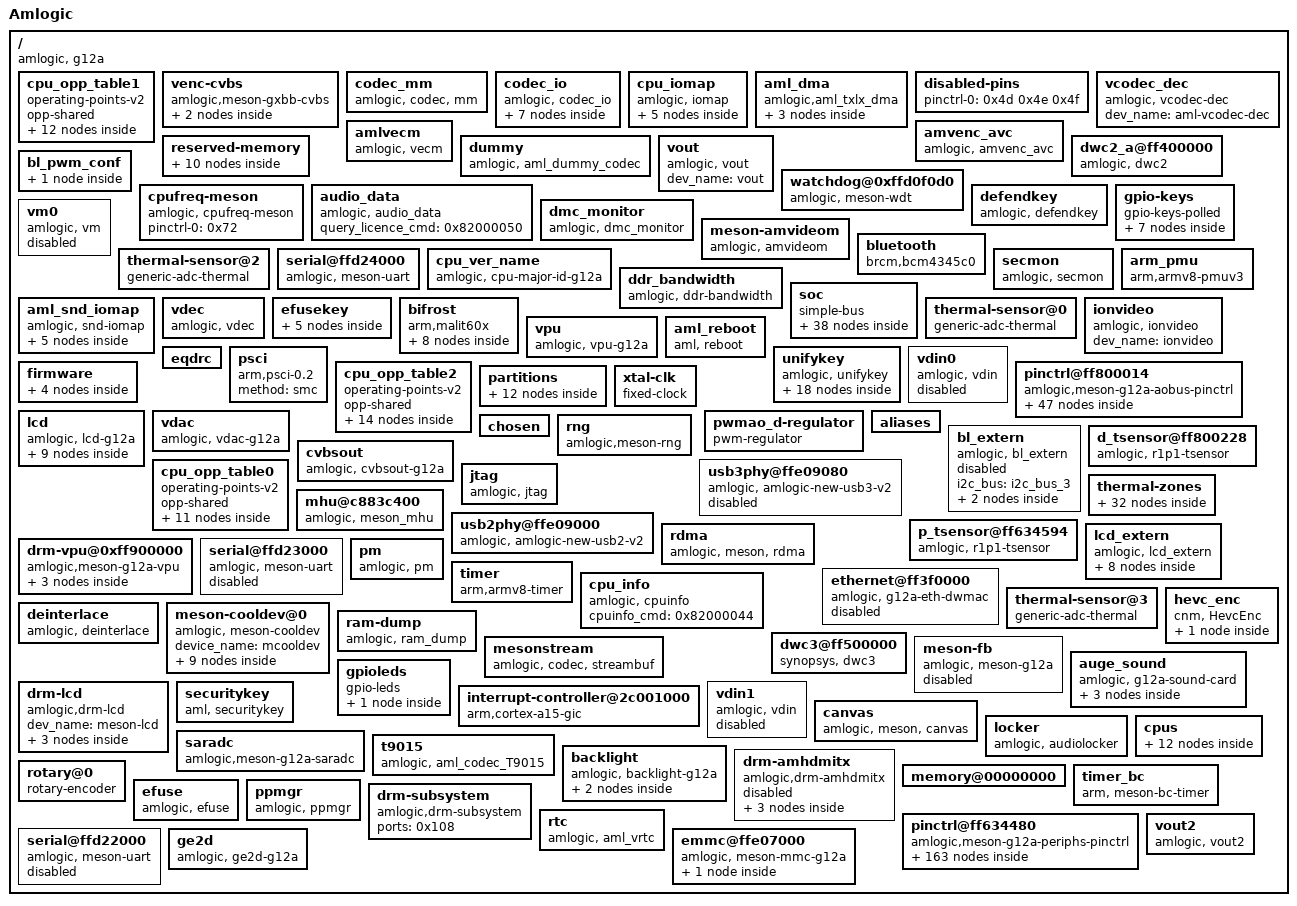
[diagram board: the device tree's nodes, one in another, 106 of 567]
/dts-v1/;

/ {
	compatible = "amlogic, g12a";
	model = "Amlogic";
	interrupt-parent = <0x01>;
	#address-cells = <0x02>;
	#size-cells = <0x02>;
	amlogic-dt-id = "g12a_evt_1g";

	cpu_opp_table1 {
		compatible = "operating-points-v2";
		phandle = <0x0e>;
		opp-shared;

		opp06 {
			opp-microvolt = <0xb9ca8>;
			opp-hz = <0x00 0x5353c980>;
		};

		opp04 {
			opp-microvolt = <0xb2778>;
			opp-hz = <0x00 0x3b9aca00>;
		};

		opp02 {
			opp-microvolt = <0xb2778>;
			opp-hz = <0x00 0x1dcd6500>;
		};

		opp10 {
			opp-microvolt = <0xef808>;
			opp-hz = <0x00 0x6b49d200>;
		};

		opp00 {
			opp-microvolt = <0xb2778>;
			opp-hz = <0x00 0x5f5e100>;
		};

		opp09 {
			opp-microvolt = <0xd2348>;
			opp-hz = <0x00 0x6590fa00>;
		};

		opp07 {
			opp-microvolt = <0xc11d8>;
			opp-hz = <0x00 0x5a1f4a00>;
		};

		opp05 {
			opp-microvolt = <0xb2778>;
			opp-hz = <0x00 0x47868c00>;
		};

		opp03 {
			opp-microvolt = <0xb2778>;
			opp-hz = <0x00 0x27c19cc0>;
		};

		opp11 {
			opp-microvolt = <0xf1f18>;
			opp-hz = <0x00 0x71b9c500>;
		};

		opp01 {
			opp-microvolt = <0xb2778>;
			opp-hz = <0x00 0xee6b280>;
		};

		opp08 {
			opp-microvolt = <0xcae18>;
			opp-hz = <0x00 0x5fd82200>;
		};
	};

	venc-cvbs {
		compatible = "amlogic,meson-gxbb-cvbs";
		status = "okay";

		ports {
			#address-cells = <0x01>;
			#size-cells = <0x00>;

			port@0 {
				#address-cells = <0x01>;
				#size-cells = <0x00>;
				phandle = <0x109>;
				reg = <0x00>;
			};
		};
	};

	codec_mm {
		compatible = "amlogic, codec, mm";
		dev_name = "codec_mm";
		status = "okay";
		memory-region = <0x51 0x52>;
	};

	codec_io {
		compatible = "amlogic, codec_io";
		ranges;
		status = "okay";
		#address-cells = <0x02>;
		#size-cells = <0x02>;
		phandle = <0xe7>;

		io_efuse_base {
			reg = <0x00 0xff630000 0x00 0x2000>;
		};

		io_cbus_base {
			reg = <0x00 0xffd00000 0x00 0x100000>;
		};

		io_dmc_base {
			reg = <0x00 0xff638000 0x00 0x2000>;
		};

		io_vcbus_base {
			reg = <0x00 0xff900000 0x00 0x40000>;
		};

		io_hiubus_base {
			reg = <0x00 0xff63c000 0x00 0x2000>;
		};

		io_aobus_base {
			reg = <0x00 0xff800000 0x00 0x10000>;
		};

		io_dos_base {
			reg = <0x00 0xff620000 0x00 0x10000>;
		};
	};

	cpu_iomap {
		compatible = "amlogic, iomap";
		ranges;
		#address-cells = <0x02>;
		#size-cells = <0x02>;

		io_apb_base {
			reg = <0x00 0xffe01000 0x00 0x7f000>;
		};

		io_cbus_base {
			reg = <0x00 0xffd00000 0x00 0x26000>;
		};

		io_vapb_base {
			reg = <0x00 0xff900000 0x00 0x50000>;
		};

		io_aobus_base {
			reg = <0x00 0xff800000 0x00 0xb000>;
		};

		io_hiu_base {
			reg = <0x00 0xff63c000 0x00 0x2000>;
		};
	};

	aml_dma {
		compatible = "amlogic,aml_txlx_dma";
		interrupts = <0x00 0xb4 0x01>;
		reg = <0x00 0xff63e000 0x00 0x48>;

		aml_tdes {
			compatible = "amlogic,tdes_dma";
			dev_name = "aml_tdes_dma";
			status = "okay";
		};

		aml_sha {
			compatible = "amlogic,sha_dma";
			dev_name = "aml_sha_dma";
			status = "okay";
		};

		aml_aes {
			compatible = "amlogic,aes_g12a_dma";
			dev_name = "aml_aes_dma";
			status = "okay";
		};
	};

	disabled-pins {
		status = "okay";
		pinctrl-0 = <0x4d 0x4e 0x4f>;
		pinctrl-names = "default";
	};

	vcodec_dec {
		compatible = "amlogic, vcodec-dec";
		dev_name = "aml-vcodec-dec";
		status = "okay";
	};

	amvenc_avc {
		compatible = "amlogic, amvenc_avc";
		dev_name = "amvenc_avc";
		status = "okay";
		interrupts = <0x00 0x2d 0x01>;
		interrupt-names = "mailbox_2";
	};

	reserved-memory {
		ranges;
		#address-cells = <0x02>;
		#size-cells = <0x02>;

		linux,ion-dev {
			reusable;
			compatible = "shared-dma-pool";
			alignment = <0x00 0x400000>;
			size = <0x00 0x8000000>;
			phandle = <0x22>;
		};

		linux,vm0_cma {
			reusable;
			compatible = "shared-dma-pool";
			alignment = <0x00 0x400000>;
			size = <0x00 0x2000000>;
			phandle = <0x55>;
		};

		ramoops@0x07400000 {
			compatible = "ramoops";
			record-size = <0x8000>;
			console-size = <0x8000>;
			ftrace-size = <0x20000>;
			reg = <0x00 0x7400000 0x00 0x100000>;
		};

		linux,meson-fb {
			reusable;
			compatible = "shared-dma-pool";
			alignment = <0x00 0x400000>;
			alloc-ranges = <0x00 0x1f800000 0x00 0x800000>;
			size = <0x00 0x800000>;
			phandle = <0x2a>;
		};

		linux,ppmgr {
			compatible = "shared-dma-pool";
			size = <0x00 0x00>;
			phandle = <0x53>;
		};

		linux,secos {
			compatible = "amlogic, aml_secos_memory";
			status = "disable";
			no-map;
			phandle = <0x101>;
			reg = <0x00 0x5300000 0x00 0x2000000>;
		};

		linux,di_cma {
			reusable;
			compatible = "shared-dma-pool";
			alignment = <0x00 0x400000>;
			size = <0x00 0x2800000>;
			phandle = <0x54>;
		};

		linux,codec_mm_cma {
			reusable;
			compatible = "shared-dma-pool";
			alignment = <0x00 0x400000>;
			size = <0x00 0x13400000>;
			phandle = <0x51>;
			linux,contiguous-region;
		};

		linux,secmon {
			reusable;
			compatible = "shared-dma-pool";
			alignment = <0x00 0x400000>;
			alloc-ranges = <0x00 0x5000000 0x00 0x400000>;
			size = <0x00 0x400000>;
			phandle = <0x11>;
		};

		linux,codec_mm_reserved {
			compatible = "amlogic, codec-mm-reserved";
			alignment = <0x00 0x100000>;
			size = <0x00 0x00>;
			phandle = <0x52>;
		};
	};

	amlvecm {
		compatible = "amlogic, vecm";
		wb_en = <0x00>;
		dev_name = "aml_vecm";
		cm_en = <0x00>;
		status = "okay";
		gamma_en = <0x00>;
		tx_op_color_primary = <0x00>;
	};

	dummy {
		compatible = "amlogic, aml_dummy_codec";
		#sound-dai-cells = <0x00>;
		status = "okay";
		phandle = <0x71>;
	};

	vout {
		compatible = "amlogic, vout";
		dev_name = "vout";
		status = "okay";
	};

	dwc2_a@ff400000 {
		port-type = <0x02>;
		compatible = "amlogic, dwc2";
		port-config = <0x00>;
		clocks = <0x02 0x41 0x02 0x49>;
		port-speed = <0x00>;
		controller-type = <0x03>;
		clock-names = "usb_general", "usb1";
		clock-src = "usb0";
		status = "okay";
		interrupts = <0x00 0x1f 0x04>;
		port-id-mode = <0x00>;
		phandle = <0xc8>;
		phy-interface = <0x00>;
		device_name = "dwc2_a";
		phy-reg = <0xffe09000>;
		usb-fifo = <0x2d8>;
		reg = <0x00 0xff400000 0x00 0x40000>;
		cpu-type = "v2";
		port-id = <0x00>;
		port-dma = <0x00>;
		pl-periph-id = <0x00>;
		phy-reg-size = <0xa0>;
	};

	watchdog@0xffd0f0d0 {
		compatible = "amlogic, meson-wdt";
		clocks = <0x16>;
		clock-names = "xtal";
		reset_watchdog_time = <0x02>;
		shutdown_timeout = <0x0a>;
		status = "okay";
		suspend_timeout = <0x06>;
		default_timeout = <0x0a>;
		phandle = <0xc9>;
		firmware_timeout = <0x06>;
		reg = <0x00 0xffd0f0d0 0x00 0x10>;
		reset_watchdog_method = <0x01>;
	};

	bl_pwm_conf {
		phandle = <0x48>;

		pwm_channel_0 {
			pwm_port_index = <0x05>;
			pwms = <0x49 0x01 0x7558 0x00>;
		};
	};

	cpufreq-meson {
		compatible = "amlogic, cpufreq-meson";
		status = "okay";
		pinctrl-0 = <0x72>;
		pinctrl-names = "default";
	};

	audio_data {
		compatible = "amlogic, audio_data";
		query_licence_cmd = <0x82000050>;
		status = "okay";
		phandle = <0xc6>;
	};

	defendkey {
		compatible = "amlogic, defendkey";
		status = "okay";
		mem_size = <0x00 0x100000>;
		phandle = <0xfd>;
		reg = <0x00 0xff630218 0x00 0x04>;
	};

	gpio-keys {
		compatible = "gpio-keys-polled";
		poll-interval = <0x28>;
		status = "okay";
		pinctrl-0 = <0x4b>;
		pinctrl-names = "default";

		back {
			gpios = <0x15 0x37 0x01>;
			label = "GPIO Key back";
			linux,code = <0x01>;
		};

		preset2 {
			gpios = <0x15 0x33 0x01>;
			label = "GPIO Key preset2";
			linux,code = <0x03>;
		};

		select {
			gpios = <0x15 0x08 0x01>;
			label = "GPIO Key select";
			linux,code = <0x1c>;
		};

		mute {
			gpios = <0x4a 0x03 0x01>;
			label = "GPIO Key mute";
			linux,code = <0x32>;
		};

		preset3 {
			gpios = <0x15 0x34 0x01>;
			label = "GPIO Key preset3";
			linux,code = <0x04>;
		};

		preset1 {
			gpios = <0x15 0x32 0x01>;
			label = "GPIO Key preset1";
			linux,code = <0x02>;
		};

		preset4 {
			gpios = <0x15 0x35 0x01>;
			label = "GPIO Key preset4";
			linux,code = <0x05>;
		};
	};

	dmc_monitor {
		compatible = "amlogic, dmc_monitor";
		status = "okay";
		interrupts = <0x00 0x33 0x01>;
		reg_base = <0xff639000>;
	};

	meson-amvideom {
		compatible = "amlogic, amvideom";
		dev_name = "amvideom";
		status = "okay";
		interrupts = <0x00 0x03 0x01>;
		interrupt-names = "vsync";
	};

	vm0 {
		compatible = "amlogic, vm";
		dev_name = "vm0";
		vm_id = <0x00>;
		status = "disabled";
		memory-region = <0x55>;
	};

	bluetooth {
		compatible = "brcm,bcm4345c0";
		host-wakeup-gpios = <0x15 0x48 0x01>;
		max-speed = <0x2dc6c0>;
		device-wakeup-gpios = <0x15 0x49 0x01>;
	};

	thermal-sensor@2 {
		io-channels = <0x50 0x02>;
		compatible = "generic-adc-thermal";
		io-channel-names = "sensor-channel";
		#thermal-sensor-cells = <0x00>;
		temperature-lookup-table = <0x14c08 0x37e 0x13880 0x36e 0x124f8 0x35c 0x11170 0x347 0xfde8 0x32f 0xea60 0x315 0xd6d8 0x2f7 0xc350 0x2d6 0xafc8 0x2b2 0x9c40 0x28a 0x88b8 0x25f 0x7530 0x230 0x61a8 0x200 0x4e20 0x1ce 0x3a98 0x19b 0x2710 0x168 0x1388 0x137 0x00 0x109 0xffffec78 0xdd 0xffffd8f0 0xb6 0xffffc568 0x93 0xffffb1e0 0x75 0xffff9e58 0x5c 0xffff8ad0 0x46 0xffff7748 0x35 0xffff63c0 0x28>;
		phandle = <0x35>;
	};

	serial@ffd24000 {
		compatible = "amlogic, meson-uart";
		clocks = <0x16 0x02 0x2e>;
		fifosize = <0x80>;
		clock-names = "clk_uart", "clk_gate";
		status = "okay";
		interrupts = <0x00 0x1a 0x01>;
		phandle = <0xe1>;
		reg = <0x00 0xffd24000 0x00 0x18>;
		pinctrl-0 = <0x27>;
		pinctrl-names = "default";
	};

	cpu_ver_name {
		compatible = "amlogic, cpu-major-id-g12a";
	};

	secmon {
		compatible = "amlogic, secmon";
		in_base_func = <0x82000020>;
		out_base_func = <0x82000021>;
		reserve_mem_size = <0x300000>;
		memory-region = <0x11>;
	};

	__symbols__ {
		phot = "/thermal-zones/soc_thermal/trips/trip-point@2";
		i2c3 = "/soc/cbus@ffd00000/i2c@1c000";
		sd_emmc_c = "/emmc@ffe07000";
		meson_cooldev = "/meson-cooldev@0";
		pwm_d_pins2 = "/pinctrl@ff634480/pwm_d_pins2";
		cpu_opp_table1 = "/cpu_opp_table1";
		pwm_a_pins = "/pinctrl@ff634480/pwm_a";
		spotify_bluetooth_bt_wake_host = "/pinctrl@ff634480/spotify_bluetooth_bt_wake_host";
		vddcpu0 = "/pwmao_d-regulator";
		pdmin = "/pinctrl@ff634480/pdmin";
		key_2 = "/efusekey/key_2";
		dvfs500_cfg = "/bifrost/dvfs500_cfg";
		spotify_imu_gpio = "/pinctrl@ff634480/spotify_imu_gpio";
		dvfs666_cfg = "/bifrost/dvfs666_cfg";
		uart_C = "/serial@ffd22000";
		usb3_phy_v2 = "/usb3phy@ffe09080";
		rt3 = "/thermal-sensor@0";
		codec_io = "/codec_io";
		spotify_mfi_i2c_pins = "/pinctrl@ff634480/spotify_mfi_i2c_pins";
		spicc1_pins = "/pinctrl@ff634480/spicc1_pins";
		keysn_15 = "/unifykey/key_15";
		i2c1_master_pins1 = "/pinctrl@ff634480/i2c1_pins1";
		logo = "/partitions/logo";
		keysn_6 = "/unifykey/key_6";
		ao_to_sd_uart_pins = "/pinctrl@ff634480/ao_to_sd_uart_pins";
		tp_int_input = "/pinctrl@ff634480/eint@0";
		sdio_x_clr_pins = "/pinctrl@ff634480/sdio_x_clr_pins";
		emmc_conf_pull_up = "/pinctrl@ff634480/emmc_conf_pull_up";
		dvfs285_cfg = "/bifrost/dvfs285_cfg";
		dvfs800_cfg = "/bifrost/dvfs800_cfg";
		spotify_disabled_pins_c = "/pinctrl@ff634480/spotify_disabled_pins_c";
		secmon_reserved = "/reserved-memory/linux,secmon";
		i2c1 = "/soc/cbus@ffd00000/i2c@1e000";
		pwm_c_pins3 = "/pinctrl@ff634480/pwm_c_pins3";
		sdio_x_all_pins = "/pinctrl@ff634480/sdio_x_all_pins";
		key_0 = "/efusekey/key_0";
		logo_reserved = "/reserved-memory/linux,meson-fb";
		sdio_clk_cmd_pins = "/pinctrl@ff634480/sdio_clk_cmd_pins";
		bl_pwm_conf = "/bl_pwm_conf";
		uart_A = "/serial@ffd24000";
		spotify_lcd_reset_pin = "/pinctrl@ff634480/spotify_lcd_reset_pin";
		ao_uart_pins = "/pinctrl@ff800014/ao_uart";
		ao_i2c_master_pins1 = "/pinctrl@ff800014/ao_i2c_pins1";
		rt1 = "/thermal-sensor@2";
		cam_dvp_pins = "/pinctrl@ff634480/cam_dvp_pins";
		state_rst_output0 = "/pinctrl@ff634480/rstoutput0";
		gpu = "/bifrost";
		keysn_13 = "/unifykey/key_13";
		dtbo_a = "/partitions/dtbo_a";
		spdifout = "/pinctrl@ff800014/spdifout";
		audio_data = "/audio_data";
		keysn_4 = "/unifykey/key_4";
		pwm_ef = "/soc/cbus@ffd00000/pwm@19000";
		meson_suspend = "/pm";
		dcritical = "/thermal-zones/ddr_thermal/trips/trip-point@3";
		pwm_ao_a_hiz_pins = "/pinctrl@ff800014/pwm_ao_a_hiz";
		defendkey = "/defendkey";
		external_eth_pins = "/pinctrl@ff634480/external_eth_pins";
		uart_AO_B = "/soc/aobus@ff800000/serial@4000";
		sd_to_ao_uart_clr_pins = "/pinctrl@ff800014/sd_to_ao_uart_clr_pins";
		jtag_apee_pins = "/pinctrl@ff634480/jtag_apee_pin";
		spotify_disabled_pins_a = "/pinctrl@ff634480/spotify_disabled_pins_a";
		a_uart_pins = "/pinctrl@ff634480/a_uart";
		periphs = "/soc/periphs@ff634400";
		internal_gpio_pins = "/pinctrl@ff634480/internal_gpio_pins";
		pinctrl_aobus = "/pinctrl@ff800014";
		pswitch_on = "/thermal-zones/soc_thermal/trips/trip-point@0";
		usb2_phy_v2 = "/usb2phy@ffe09000";
		gpio = "/pinctrl@ff634480/banks@ff6346c0";
		bl_enable = "/pinctrl@ff634480/bl_enable";
		pwm_c_pins1 = "/pinctrl@ff634480/pwm_c_pins1";
		pwm_ao_d_pins2 = "/pinctrl@ff800014/pwm_ao_d_pins2";
		emmc_conf_pull_done = "/pinctrl@ff634480/emmc_conf_pull_done";
		ion_cma_reserved = "/reserved-memory/linux,ion-dev";
		misc = "/partitions/misc";
		spotify_touch_i2c = "/pinctrl@ff634480/spotify_touch_i2c";
		dvfs250_cfg = "/bifrost/dvfs250_cfg";
		system_b = "/partitions/system_b";
		audioresample = "/soc/audiobus@0xff642000/resample";
		keysn_11 = "/unifykey/key_11";
		pwm_f_pins1 = "/pinctrl@ff634480/pwm_f_pins1";
		codec_mm_reserved = "/reserved-memory/linux,codec_mm_reserved";
		spotify_bluetooth_host_wake_bt = "/pinctrl@ff634480/spotify_bluetooth_host_wake_bt";
		keysn_2 = "/unifykey/key_2";
		i2c2_master_pins1 = "/pinctrl@ff634480/i2c2_pins1";
		gpufreq_cool0 = "/meson-cooldev@0/gpufreq_cool0";
		eecec_a = "/pinctrl@ff634480/ee_ceca";
		spicc0 = "/soc/cbus@ffd00000/spi@13000";
		jtag_apao_pins = "/pinctrl@ff800014/jtag_apao_pin";
		secos_reserved = "/reserved-memory/linux,secos";
		pwm_b_pins2 = "/pinctrl@ff634480/pwm_b_pins2";
		irblaster_pins = "/pinctrl@ff800014/irblaster_pin";
		i2c0_master_pins2 = "/pinctrl@ff634480/i2c0_pins2";
		pwm_cd = "/soc/cbus@ffd00000/pwm@1a000";
		pcontrol = "/thermal-zones/soc_thermal/trips/trip-point@1";
		dvfs850_cfg = "/bifrost/dvfs850_cfg";
		cbus = "/soc/cbus@ffd00000";
		bt_pswitchon = "/thermal-zones/bluetooth_thermal/trips/bt_pswitchon";
		dhot = "/thermal-zones/ddr_thermal/trips/trip-point@2";
		spotify_disabled_pins_h = "/pinctrl@ff634480/spotify_disabled_pins_h";
		keysn_0 = "/unifykey/key_0";
		codec_mm_cma = "/reserved-memory/linux,codec_mm_cma";
		p_tsensor = "/p_tsensor@ff634594";
		efusekey = "/efusekey";
		gic = "/interrupt-controller@2c001000";
		audiolocker = "/locker";
		aocec_a = "/pinctrl@ff800014/ao_ceca";
		pdm_codec = "/dummy";
		remote_pins = "/pinctrl@ff800014/remote_pin";
		di_cma_reserved = "/reserved-memory/linux,di_cma";
		pwm_ao_c_pins1 = "/pinctrl@ff800014/pwm_ao_c_pins1";
		pcb_pcontrol = "/thermal-zones/pcb_thermal/trips/pcb_pcontrol";
		nand_cs_pins = "/pinctrl@ff634480/nand_cs";
		pwm_e_pins = "/pinctrl@ff634480/pwm_e";
		ddr_thermal = "/thermal-zones/ddr_thermal";
		vdin0 = "/vdin0";
		i2c_AO = "/soc/aobus@ff800000/i2c@5000";
		vbmeta_a = "/partitions/vbmeta_a";
		dram_pswitchon = "/thermal-zones/dram_thermal/trips/dram_pswitchon";
		keysn_9 = "/unifykey/key_9";
		gen_clk_ee_z = "/pinctrl@ff634480/gen_clk_ee_z";
		CPU2 = "/cpus/cpu@2";
		boot_b = "/partitions/boot_b";
		cpu_opp_table2 = "/cpu_opp_table2";
		partitions = "/partitions";
		pinctrl_periphs = "/pinctrl@ff634480";
		sd_clr_all_pins = "/pinctrl@ff634480/sd_clr_all_pins";
		pwm_ab = "/soc/cbus@ffd00000/pwm@1b000";
		cpufreq_cool0 = "/meson-cooldev@0/cpufreq_cool0";
		lcd = "/lcd";
		i2c3_master_pins1 = "/pinctrl@ff634480/i2c3_pins1";
		key_3 = "/efusekey/key_3";
		aobus = "/soc/aobus@ff800000";
		clkc = "/soc/hiubus@ff63c000/clock-controller@0";
		all_nand_pins = "/pinctrl@ff634480/all_nand_pins";
		keysn_16 = "/unifykey/key_16";
		pwm_ao_b_pins = "/pinctrl@ff800014/pwm_ao_b";
		i2c1_master_pins2 = "/pinctrl@ff634480/i2c1_pins2";
		tdmin_a = "/pinctrl@ff634480/tdmin_a";
		keysn_7 = "/unifykey/key_7";
		sd_all_pins = "/pinctrl@ff634480/sd_all_pins";
		wdt = "/watchdog@0xffd0f0d0";
		ao_i2c_slave_pins = "/pinctrl@ff800014/ao_i2c_slave_pins";
		aml_loopback = "/soc/audiobus@0xff642000/loopback";
		spotify_rotary = "/pinctrl@ff634480/spotify_rotary";
		CPU0 = "/cpus/cpu@0";
		i2c2 = "/soc/cbus@ffd00000/i2c@1d000";
		pwm_d_pins1 = "/pinctrl@ff634480/pwm_d_pins1";
		cpu_opp_table0 = "/cpu_opp_table0";
		i2c_AO_slave = "/soc/aobus@ff800000/i2c_slave@6000";
		audiobus = "/soc/audiobus@0xff642000";
		key_1 = "/efusekey/key_1";
		b_uart_pins = "/pinctrl@ff634480/b_uart";
		dummy_codec = "/dummy";
		uart_B = "/serial@ffd23000";
		ao_i2c_master_pins2 = "/pinctrl@ff800014/ao_i2c_pins2";
		rt2 = "/thermal-sensor@3";
		state_rst_output1 = "/pinctrl@ff634480/rstoutput1";
		keysn_14 = "/unifykey/key_14";
		dtbo_b = "/partitions/dtbo_b";
		dswitch_on = "/thermal-zones/ddr_thermal/trips/trip-point@0";
		keysn_5 = "/unifykey/key_5";
		spicc0_pins_x = "/pinctrl@ff634480/spicc0_pins_x";
		dcontrol = "/thermal-zones/ddr_thermal/trips/trip-point@1";
		internal_eth_pins = "/pinctrl@ff634480/internal_eth_pins";
		spotify_prox_gpio = "/pinctrl@ff634480/spotify_prox_gpio";
		dvfs125_cfg = "/bifrost/clk125_cfg";
		sdio_x_en_pins = "/pinctrl@ff634480/sdio_x_en_pins";
		hdmitx_ddc = "/pinctrl@ff634480/hdmitx_ddc";
		gpio_intc = "/soc/cbus@ffd00000/interrupt-controller@f080";
		i2c0 = "/soc/cbus@ffd00000/i2c@1f000";
		bt_pcontrol = "/thermal-zones/bluetooth_thermal/trips/bt_pcontrol";
		pwm_c_pins2 = "/pinctrl@ff634480/pwm_c_pins2";
		pwm_ao_d_pins3 = "/pinctrl@ff800014/pwm_ao_d_pins3";
		sd_clk_cmd_pins = "/pinctrl@ff634480/sd_clk_cmd_pins";
		dram_pcontrol = "/thermal-zones/dram_thermal/trips/dram_pcontrol";
		pwm_ao_a_pins = "/pinctrl@ff800014/pwm_ao_a";
		vm0_cma_reserved = "/reserved-memory/linux,vm0_cma";
		d_tsensor = "/d_tsensor@ff800228";
		aml_tdma = "/soc/audiobus@0xff642000/tdma";
		sd_to_ao_uart_pins = "/pinctrl@ff800014/sd_to_ao_uart_pins";
		spdifin = "/pinctrl@ff634480/spdifin";
		pcb_pswitchon = "/thermal-zones/pcb_thermal/trips/pcb_pswitchon";
		dvfs400_cfg = "/bifrost/dvfs400_cfg";
		cluster0 = "/cpus/cpu-map/cluster0";
		CPU_SLEEP_0 = "/cpus/idle-states/cpu-sleep-0";
		amlogic_codec = "/t9015";
		pcb_critical = "/thermal-zones/pcb_thermal/trips/pcb_critical";
		tdmout_a = "/pinctrl@ff634480/tdmout_a";
		keysn_12 = "/unifykey/key_12";
		pwm_f_pins2 = "/pinctrl@ff634480/pwm_f_pins2";
		hiubus = "/soc/hiubus@ff63c000";
		sd_1bit_pins = "/pinctrl@ff634480/sd_1bit_pins";
		keysn_3 = "/unifykey/key_3";
		i2c2_master_pins2 = "/pinctrl@ff634480/i2c2_pins2";
		spicc0_pins_c = "/pinctrl@ff634480/spicc0_pins_c";
		eecec_b = "/pinctrl@ff634480/ee_cecb";
		ppmgr_reserved = "/reserved-memory/linux,ppmgr";
		spicc1 = "/soc/cbus@ffd00000/spi@15000";
		dwc2_a = "/dwc2_a@ff400000";
		spotify_buttons = "/pinctrl@ff634480/spotify_buttons";
		pwm_ao_d_pins1 = "/pinctrl@ff800014/pwm_ao_d_pins1";
		gpucore_cool0 = "/meson-cooldev@0/gpucore_cool0";
		i2c0_master_pins3 = "/pinctrl@ff634480/i2c0_pins3";
		soc_thermal = "/thermal-zones/soc_thermal";
		settings = "/partitions/settings";
		gpio_ao = "/pinctrl@ff800014/ao-bank@ff800014";
		data = "/partitions/data";
		pwm_ao_c_hiz_pins = "/pinctrl@ff800014/pwm_ao_c_hiz";
		system_a = "/partitions/system_a";
		clkaudio = "/soc/audiobus@0xff642000/audio_clocks";
		xtal = "/xtal-clk";
		keysn_10 = "/unifykey/key_10";
		keysn_1 = "/unifykey/key_1";
		pwm_AO_cd = "/soc/aobus@ff800000/pwm@2000";
		uart_AO = "/soc/aobus@ff800000/serial@3000";
		aocec_b = "/pinctrl@ff800014/ao_cecb";
		audio_effect = "/eqdrc";
		pwm_b_pins1 = "/pinctrl@ff634480/pwm_b_pins1";
		pwm_ao_c_pins2 = "/pinctrl@ff800014/pwm_ao_c_pins2";
		ethmac = "/ethernet@ff3f0000";
		pcritical = "/thermal-zones/soc_thermal/trips/trip-point@3";
		i2c0_master_pins1 = "/pinctrl@ff634480/i2c0_pins1";
		vdin1 = "/vdin1";
		vbmeta_b = "/partitions/vbmeta_b";
		aoclkc = "/soc/aobus@ff800000/clock-controller@0";
		canvas = "/canvas";
		cpus = "/cpus";
		saradc = "/saradc";
		aml_pdm = "/soc/audiobus@0xff642000/pdm";
		sdio_all_pins = "/pinctrl@ff634480/sdio_all_pins";
		sd_clr_noall_pins = "/pinctrl@ff634480/sd_clr_noall_pins";
		CPU3 = "/cpus/cpu@3";
		bl_pwm_off_pins = "/pinctrl@ff634480/bl_pwm_off_pin";
		spdifout_a_mute = "/pinctrl@ff800014/spdifout_a_mute";
		i2c3_master_pins2 = "/pinctrl@ff634480/i2c3_pins2";
		sdio_x_clk_cmd_pins = "/pinctrl@ff634480/sdio_x_clk_cmd_pins";
		efuse = "/efuse";
		key_4 = "/efusekey/key_4";
		dwc3 = "/dwc3@ff500000";
		irblaster = "/soc/aobus@ff800000/meson-irblaster@14c";
		ao_b_uart_pins = "/pinctrl@ff800014/ao_b_uart";
		mailbox = "/mhu@c883c400";
		bt_critical = "/thermal-zones/bluetooth_thermal/trips/bt_critical";
		dram_critical = "/thermal-zones/dram_thermal/trips/dram_critical";
		cpucore_cool0 = "/meson-cooldev@0/cpucore_cool0";
		c_uart_pins = "/pinctrl@ff634480/c_uart";
		pwm_AO_ab = "/soc/aobus@ff800000/pwm@7000";
		keysn_17 = "/unifykey/key_17";
		i2c1_master_pins3 = "/pinctrl@ff634480/i2c1_pins3";
		keysn_8 = "/unifykey/key_8";
		hdmitx_hpd = "/pinctrl@ff634480/hdmitx_hpd";
		emmc_clk_cmd_pins = "/pinctrl@ff634480/emmc_clk_cmd_pins";
		clk12_24_z_pins = "/pinctrl@ff634480/clk12_24_z_pins";
		spotify_touch_gpio = "/pinctrl@ff634480/spotify_touch_gpio";
		meson_fb = "/meson-fb";
		CPU1 = "/cpus/cpu@1";
		hdmitx_hpd_gpio = "/pinctrl@ff634480/hdmitx_hpd_gpio";
		boot_a = "/partitions/boot_a";
	};

	ddr_bandwidth {
		compatible = "amlogic, ddr-bandwidth";
		status = "okay";
		interrupts = <0x00 0x34 0x01>;
		reg = <0x00 0xff638000 0x00 0x100 0x00 0xff638c00 0x00 0x100>;
		interrupt-names = "ddr_bandwidth";
	};

	arm_pmu {
		compatible = "arm,armv8-pmuv3";
		max-wait-cnt = <0x2710>;
		cpumasks = <0x0f>;
		interrupts = <0x00 0x89 0x04>;
		reg = <0x00 0xff634680 0x00 0x04>;
		relax-timer-ns = <0x989680>;
	};

	soc {
		compatible = "simple-bus";
		ranges;
		#address-cells = <0x02>;
		#size-cells = <0x02>;

		aobus@ff800000 {
			compatible = "simple-bus";
			ranges = <0x00 0x00 0x00 0xff800000 0x00 0xb000>;
			#address-cells = <0x02>;
			#size-cells = <0x02>;
			phandle = <0xd4>;
			reg = <0x00 0xff800000 0x00 0xb000>;

			meson-irblaster@14c {
				compatible = "amlogic, meson_irblaster";
				#irblaster-cells = <0x02>;
				status = "disabled";
				interrupts = <0x00 0xc6 0x01>;
				phandle = <0xdb>;
				reg = <0x00 0x14c 0x00 0x10 0x00 0x40 0x00 0x04>;
				pinctrl-0 = <0x21>;
				pinctrl-names = "default";
			};

			pwm@2000 {
				compatible = "amlogic,g12a-ao-pwm";
				clocks = <0x16 0x16 0x16 0x16>;
				clock-names = "clkin0", "clkin1", "clkin2", "clkin3";
				status = "okay";
				phandle = <0x38>;
				reg = <0x00 0x2000 0x00 0x20>;
				#pwm-cells = <0x03>;
			};

			i2c@5000 {
				compatible = "amlogic,meson-g12a-i2c";
				clocks = <0x02 0x2a>;
				clock-names = "clk_i2c";
				status = "disabled";
				#address-cells = <0x01>;
				interrupts = <0x00 0xc3 0x01 0x00 0xc9 0x01>;
				#size-cells = <0x00>;
				phandle = <0xd7>;
				reg = <0x00 0x5000 0x00 0x20>;
			};

			clock-controller@0 {
				compatible = "amlogic,g12a-aoclkc";
				#clock-cells = <0x01>;
				phandle = <0xd5>;
				reg = <0x00 0x00 0x00 0x320>;
			};

			pwm@7000 {
				compatible = "amlogic,g12a-ao-pwm";
				clocks = <0x16 0x16 0x16 0x16>;
				clock-names = "clkin0", "clkin1", "clkin2", "clkin3";
				status = "disabled";
				phandle = <0xd6>;
				reg = <0x00 0x7000 0x00 0x20>;
				#pwm-cells = <0x03>;
			};

			cpu_version {
				reg = <0x00 0x220 0x00 0x04>;
			};

			serial@4000 {
				compatible = "amlogic, meson-uart";
				clocks = <0x16>;
				fifosize = <0x40>;
				clock-names = "clk_uart";
				status = "disabled";
				interrupts = <0x00 0xc5 0x01>;
				phandle = <0xda>;
				reg = <0x00 0x4000 0x00 0x18>;
				pinctrl-0 = <0x20>;
				pinctrl-names = "default";
			};

			i2c_slave@6000 {
				compatible = "amlogic, meson-i2c-slave";
				status = "disabled";
				interrupts = <0x00 0xc2 0x01>;
				phandle = <0xd8>;
				reg = <0x00 0x6000 0x00 0x20>;
				pinctrl-0 = <0x1e>;
				pinctrl-names = "default";
			};

			serial@3000 {
				compatible = "amlogic, meson-uart";
				clocks = <0x16>;
				xtal_tick_en = <0x02>;
				fifosize = <0x40>;
				clock-names = "clk_uart";
				status = "okay";
				interrupts = <0x00 0xc1 0x01>;
				phandle = <0xd9>;
				reg = <0x00 0x3000 0x00 0x18>;
				pinctrl-0 = <0x1f>;
				support-sysrq = <0x00>;
				pinctrl-names = "default";
			};
		};

		periphs@ff634400 {
			compatible = "simple-bus";
			ranges = <0x00 0x00 0x00 0xff634400 0x00 0x400>;
			#address-cells = <0x02>;
			#size-cells = <0x02>;
			phandle = <0xdc>;
			reg = <0x00 0xff634400 0x00 0x400>;
		};

		audiobus@0xff642000 {
			compatible = "amlogic, audio-controller", "simple-bus";
			ranges = <0x00 0x00 0x00 0xff642000 0x00 0x2000>;
			#address-cells = <0x02>;
			#size-cells = <0x02>;
			phandle = <0xde>;
			reg = <0x00 0xff642000 0x00 0x2000>;

			pdm {
				compatible = "amlogic, g12a-snd-pdm";
				clocks = <0x23 0x01 0x02 0x03 0x02 0x0f 0x23 0x1f 0x23 0x20>;
				#sound-dai-cells = <0x00>;
				clock-names = "gate", "sysclk_srcpll", "dclk_srcpll", "pdm_dclk", "pdm_sysclk";
				status = "okay";
				phandle = <0x70>;
				filter_mode = <0x01>;
				pinctrl-0 = <0x26>;
				pinctrl-names = "pdm_pins";
			};

			resample {
				compatible = "amlogic, g12a-resample";
				clocks = <0x02 0x0f 0x23 0x1c 0x23 0x24>;
				clock-names = "resample_pll", "resample_src", "resample_clk";
				status = "okay";
				phandle = <0xe0>;
				resample_module = <0x04>;
			};

			ddr_manager {
				compatible = "amlogic, g12a-audio-ddr-manager";
				interrupts = <0x00 0x94 0x01 0x00 0x95 0x01 0x00 0x96 0x01 0x00 0x98 0x01 0x00 0x99 0x01 0x00 0x9a 0x01>;
				interrupt-names = "toddr_a", "toddr_b", "toddr_c", "frddr_a", "frddr_b", "frddr_c";
			};

			audio_clocks {
				compatible = "amlogic, g12a-audio-clocks";
				#clock-cells = <0x01>;
				phandle = <0x23>;
				reg = <0x00 0x00 0x00 0xb0>;
			};

			loopback {
				datalb-lane-mask-in = <0x00 0x01>;
				compatible = "amlogic, snd-loopback";
				clocks = <0x02 0x0d>;
				datain_chmask = <0x3f>;
				clock-names = "datalb_mpll";
				datain_src = <0x04>;
				datain_chnum = <0x08>;
				status = "okay";
				phandle = <0x6d>;
				datalb_chnum = <0x02>;
				datalb_src = <0x00>;
				datalb_chmask = <0x03>;
				lb_mode = <0x00>;
			};

			tdma {
				dai-tdm-clk-sel = <0x00>;
				compatible = "amlogic, g12a-snd-tdma";
				clocks = <0x23 0x17 0x02 0x0c>;
				#sound-dai-cells = <0x00>;
				clock-names = "mclk", "clk_srcpll";
				dai-tdm-oe-lane-slot-mask-out = <0x01 0x00>;
				dai-tdm-lane-slot-mask-in = <0x00 0x01>;
				phandle = <0xdf>;
				pinctrl-0 = <0x24 0x25>;
				pinctrl-names = "tdm_pins";
			};
		};

		ion_dev {
			compatible = "amlogic, ion_dev";
			memory-region = <0x22>;
		};

		cbus@ffd00000 {
			compatible = "simple-bus";
			ranges = <0x00 0x00 0x00 0xffd00000 0x00 0x26000>;
			#address-cells = <0x02>;
			#size-cells = <0x02>;
			phandle = <0xca>;
			reg = <0x00 0xffd00000 0x00 0x26000>;

			pwm@1b000 {
				compatible = "amlogic,g12a-ee-pwm";
				clocks = <0x16 0x16 0x16 0x16>;
				clock-names = "clkin0", "clkin1", "clkin2", "clkin3";
				status = "disabled";
				phandle = <0xcc>;
				reg = <0x00 0x1b000 0x00 0x20>;
				#pwm-cells = <0x03>;
			};

			i2c@1d000 {
				compatible = "amlogic,meson-g12a-i2c";
				clocks = <0x02 0x2a>;
				clock-names = "clk_i2c";
				status = "okay";
				#address-cells = <0x01>;
				interrupts = <0x00 0xd7 0x01 0x00 0x5e 0x01>;
				#size-cells = <0x00>;
				phandle = <0xd0>;
				reg = <0x00 0x1d000 0x00 0x20>;
				clock-frequency = <0x61a80>;
				pinctrl-0 = <0x1a 0x1b 0x1c>;
				pinctrl-names = "default";

				tmd27721@39 {
					compatible = "amstaos,tmd2772";
					enable-als = "true";
					enable-proxy = "false";
					reg = <0x39>;
				};

				max20332@35 {
					reg = <0x35>;
				};

				lis2dh12@18 {
					compatible = "st,lis2dh12-accel";
					reg = <0x18>;
				};
			};

			pwm@1a000 {
				compatible = "amlogic,g12a-ee-pwm";
				clocks = <0x16 0x16 0x16 0x16>;
				clock-names = "clkin0", "clkin1", "clkin2", "clkin3";
				status = "disabled";
				phandle = <0xcd>;
				reg = <0x00 0x1a000 0x00 0x20>;
				#pwm-cells = <0x03>;
			};

			spi@13000 {
				compatible = "amlogic,meson-g12a-spicc";
				clocks = <0x02 0x29 0x02 0xd1>;
				clock-names = "core", "comp";
				status = "disabled";
				#address-cells = <0x01>;
				interrupts = <0x00 0x51 0x04>;
				#size-cells = <0x00>;
				phandle = <0xd2>;
				reg = <0x00 0x13000 0x00 0x44>;
			};

			i2c@1f000 {
				compatible = "amlogic,meson-g12a-i2c";
				clocks = <0x02 0x2a>;
				clock-names = "clk_i2c";
				status = "okay";
				#address-cells = <0x01>;
				interrupts = <0x00 0x15 0x01 0x00 0x5b 0x01>;
				#size-cells = <0x00>;
				phandle = <0xce>;
				reg = <0x00 0x1f000 0x00 0x20>;
				clock-frequency = <0x61a80>;
				pinctrl-0 = <0x19>;
				pinctrl-names = "default";

				tlsc6x_ts@2e {
					TP_MAX_Y = <0x320>;
					reset-gpio = <0x15 0x04 0x00>;
					compatible = "tlsc6x,tlsc6x_ts";
					status = "okay";
					TP_MAX_X = <0x1e0>;
					polling-mode = <0x00>;
					reg = <0x2e>;
					irq-gpio = <0x15 0x05 0x00>;
				};
			};

			i2c@1c000 {
				compatible = "amlogic,meson-g12a-i2c";
				clocks = <0x02 0x2a>;
				clock-names = "clk_i2c";
				status = "okay";
				#address-cells = <0x01>;
				interrupts = <0x00 0x27 0x01 0x00 0x5f 0x01>;
				#size-cells = <0x00>;
				phandle = <0xd1>;
				reg = <0x00 0x1c000 0x00 0x20>;
				clock-frequency = <0x61a80>;
				pinctrl-0 = <0x1d>;
				pinctrl-names = "default";

				mfi@10 {
					compatible = "apple_mfi_auth";
					reg = <0x10>;
				};
			};

			meson_clk_msr {
				compatible = "amlogic, gxl_measure";
				ringctrl = <0xff6345fc>;
				reg = <0x00 0x18004 0x00 0x04 0x00 0x1800c 0x00 0x04>;
			};

			interrupt-controller@f080 {
				compatible = "amlogic,meson-gpio-intc-ext", "amlogic,meson-g12a-gpio-intc";
				status = "okay";
				#interrupt-cells = <0x02>;
				phandle = <0xcb>;
				reg = <0x00 0xf080 0x00 0x10>;
				amlogic,channel-interrupts = <0x40 0x41 0x42 0x43 0x44 0x45 0x46 0x47>;
				interrupt-controller;
			};

			spi@15000 {
				compatible = "amlogic,meson-g12a-spicc";
				clocks = <0x02 0x2f 0x02 0xd5>;
				clock-names = "core", "comp";
				status = "disabled";
				#address-cells = <0x01>;
				interrupts = <0x00 0x5a 0x04>;
				#size-cells = <0x00>;
				phandle = <0xd3>;
				reg = <0x00 0x15000 0x00 0x44>;
			};

			i2c@1e000 {
				compatible = "amlogic,meson-g12a-i2c";
				clocks = <0x02 0x2a>;
				clock-names = "clk_i2c";
				status = "disabled";
				#address-cells = <0x01>;
				interrupts = <0x00 0xd6 0x01 0x00 0x5c 0x01>;
				#size-cells = <0x00>;
				phandle = <0xcf>;
				reg = <0x00 0x1e000 0x00 0x20>;
			};

			pwm@19000 {
				compatible = "amlogic,g12a-ee-pwm";
				clocks = <0x16 0x16 0x16 0x16>;
				clock-names = "clkin0", "clkin1", "clkin2", "clkin3";
				status = "okay";
				phandle = <0x49>;
				reg = <0x00 0x19000 0x00 0x20>;
				#pwm-cells = <0x03>;
			};
		};

		hiubus@ff63c000 {
			compatible = "simple-bus";
			ranges = <0x00 0x00 0x00 0xff63c000 0x00 0x2000>;
			#address-cells = <0x02>;
			#size-cells = <0x02>;
			phandle = <0xdd>;
			reg = <0x00 0xff63c000 0x00 0x2000>;

			clock-controller@0 {
				compatible = "amlogic,g12a-clkc";
				#clock-cells = <0x01>;
				phandle = <0x02>;
				reg = <0x00 0x00 0x00 0x320>;
			};
		};
	};

	aml_snd_iomap {
		compatible = "amlogic, snd-iomap";
		ranges;
		status = "okay";
		#address-cells = <0x02>;
		#size-cells = <0x02>;

		reset_base {
			reg = <0x00 0xffd01000 0x00 0x1000>;
		};

		pdm_bus {
			reg = <0x00 0xff640000 0x00 0x2000>;
		};

		eqdrc_base {
			reg = <0x00 0xff642800 0x00 0x1800>;
		};

		audiolocker_base {
			reg = <0x00 0xff64a000 0x00 0x2000>;
		};

		audiobus_base {
			reg = <0x00 0xff642000 0x00 0x2000>;
		};
	};

	vdec {
		compatible = "amlogic, vdec";
		dev_name = "vdec.0";
		status = "okay";
		interrupts = <0x00 0x03 0x01 0x00 0x17 0x01 0x00 0x20 0x01 0x00 0x2b 0x01 0x00 0x2c 0x01 0x00 0x2d 0x01>;
		interrupt-names = "vsync", "demux", "parser", "mailbox_0", "mailbox_1", "mailbox_2";
	};

	efusekey {
		key3 = <0x6b>;
		keynum = <0x05>;
		key1 = <0x69>;
		key4 = <0x6c>;
		key2 = <0x6a>;
		phandle = <0x39>;
		key0 = <0x68>;

		key_2 {
			offset = <0x0c>;
			keyname = "mac_wifi";
			size = <0x06>;
			phandle = <0x6a>;
		};

		key_0 {
			offset = <0x00>;
			keyname = "mac";
			size = <0x06>;
			phandle = <0x68>;
		};

		key_3 {
			offset = <0x12>;
			keyname = "usid";
			size = <0x10>;
			phandle = <0x6b>;
		};

		key_1 {
			offset = <0x06>;
			keyname = "mac_bt";
			size = <0x06>;
			phandle = <0x69>;
		};

		key_4 {
			offset = <0x22>;
			keyname = "f_serial";
			size = <0x0f>;
			phandle = <0x6c>;
		};
	};

	bifrost {
		compatible = "arm,malit60x", "arm,malit6xx", "arm,mali-midgard";
		clocks = <0x02 0x83 0x02 0x07>;
		sc_mpp = <0x01>;
		clock-names = "gpu_mux", "gp0_pll";
		tbl = <0x03 0x04 0x05 0x06 0x07 0x07>;
		interrupt-parent = <0x01>;
		interrupts = <0x00 0xa0 0x04 0x00 0xa1 0x04 0x00 0xa2 0x04>;
		phandle = <0x73>;
		reg = <0x00 0xffe40000 0x00 0x4000 0x00 0xffd01000 0x00 0x1000 0x00 0xff800000 0x00 0x1000 0x00 0xff63c000 0x00 0x1000 0x00 0xffd01000 0x00 0x1000>;
		#cooling-cells = <0x02>;
		interrupt-names = "GPU", "MMU", "JOB";
		num_of_pp = <0x02>;

		dvfs500_cfg {
			clk_reg = <0xa00>;
			voltage = <0x47e>;
			threshold = <0xb4 0xdc>;
			clk_parent = "fclk_div4";
			clkp_freq = <0x1dcd6500>;
			keep_count = <0x05>;
			clk_freq = <0x1dcd6500>;
			phandle = <0x05>;
		};

		dvfs666_cfg {
			clk_reg = <0x800>;
			voltage = <0x47e>;
			threshold = <0xd2 0xec>;
			clk_parent = "fclk_div3";
			clkp_freq = <0x27bc86aa>;
			keep_count = <0x05>;
			clk_freq = <0x27bc86aa>;
			phandle = <0x06>;
		};

		dvfs285_cfg {
			clk_reg = <0xe00>;
			voltage = <0x47e>;
			threshold = <0x64 0xbe>;
			clk_parent = "fclk_div7";
			clkp_freq = <0x1107a76d>;
			keep_count = <0x05>;
			clk_freq = <0x1107a76d>;
			phandle = <0x03>;
		};

		dvfs800_cfg {
			clk_reg = <0x600>;
			voltage = <0x47e>;
			threshold = <0xe6 0xff>;
			clk_parent = "fclk_div2p5";
			clkp_freq = <0x2faf0800>;
			keep_count = <0x05>;
			clk_freq = <0x2faf0800>;
			phandle = <0x76>;
		};

		clk125_cfg {
			clk_reg = <0xa03>;
			voltage = <0x47e>;
			threshold = <0x1e 0x78>;
			clk_parent = "fclk_div4";
			clkp_freq = <0x1dcd6500>;
			keep_count = <0x05>;
			clk_freq = <0x7735940>;
			phandle = <0x74>;
		};

		dvfs250_cfg {
			clk_reg = <0xa01>;
			voltage = <0x47e>;
			threshold = <0x50 0xaa>;
			clk_parent = "fclk_div4";
			clkp_freq = <0x1dcd6500>;
			keep_count = <0x05>;
			clk_freq = <0xee6b280>;
			phandle = <0x75>;
		};

		dvfs850_cfg {
			clk_reg = <0x200>;
			voltage = <0x47e>;
			threshold = <0xe6 0xff>;
			clk_parent = "gp0_pll";
			clkp_freq = <0x326cef80>;
			keep_count = <0x05>;
			clk_freq = <0x326cef80>;
			phandle = <0x07>;
		};

		dvfs400_cfg {
			clk_reg = <0xc00>;
			voltage = <0x47e>;
			threshold = <0x98 0xcf>;
			clk_parent = "fclk_div5";
			clkp_freq = <0x17d78400>;
			keep_count = <0x05>;
			clk_freq = <0x17d78400>;
			phandle = <0x04>;
		};
	};

	thermal-sensor@0 {
		io-channels = <0x50 0x00>;
		compatible = "generic-adc-thermal";
		io-channel-names = "sensor-channel";
		#thermal-sensor-cells = <0x00>;
		temperature-lookup-table = <0x14c08 0x37e 0x13880 0x36e 0x124f8 0x35c 0x11170 0x347 0xfde8 0x32f 0xea60 0x315 0xd6d8 0x2f7 0xc350 0x2d6 0xafc8 0x2b2 0x9c40 0x28a 0x88b8 0x25f 0x7530 0x230 0x61a8 0x200 0x4e20 0x1ce 0x3a98 0x19b 0x2710 0x168 0x1388 0x137 0x00 0x109 0xffffec78 0xdd 0xffffd8f0 0xb6 0xffffc568 0x93 0xffffb1e0 0x75 0xffff9e58 0x5c 0xffff8ad0 0x46 0xffff7748 0x35 0xffff63c0 0x28>;
		phandle = <0x37>;
	};

	ionvideo {
		compatible = "amlogic, ionvideo";
		dev_name = "ionvideo";
		status = "okay";
	};

	vpu {
		compatible = "amlogic, vpu-g12a";
		clocks = <0x02 0x95 0x02 0x4c 0x02 0x87 0x02 0x8b 0x02 0x8c>;
		dev_name = "vpu";
		clock-names = "vapb_clk", "vpu_intr_gate", "vpu_clk0", "vpu_clk1", "vpu_clk";
		status = "okay";
		clk_level = <0x07>;
	};

	aml_reboot {
		compatible = "aml, reboot";
		sys_reset = <0x84000009>;
		sys_poweroff = <0x84000008>;
	};

	eqdrc {
		eqdrc_module = <0x01>;
		lane_mask = <0x01>;
		phandle = <0x6f>;
		channel_mask = <0x03>;
	};

	psci {
		compatible = "arm,psci-0.2";
		method = "smc";
	};

	unifykey {
		unifykey-index-10 = <0x60>;
		compatible = "amlogic, unifykey";
		unifykey-index-7 = <0x5d>;
		unifykey-index-17 = <0x67>;
		unifykey-index-5 = <0x5b>;
		unifykey-index-15 = <0x65>;
		unifykey-index-3 = <0x59>;
		unifykey-num = <0x12>;
		unifykey-index-13 = <0x63>;
		unifykey-index-1 = <0x57>;
		unifykey-index-11 = <0x61>;
		status = "ok";
		unifykey-index-8 = <0x5e>;
		unifykey-index-6 = <0x5c>;
		unifykey-index-16 = <0x66>;
		unifykey-index-4 = <0x5a>;
		unifykey-index-14 = <0x64>;
		unifykey-index-2 = <0x58>;
		unifykey-index-12 = <0x62>;
		unifykey-index-0 = <0x56>;
		unifykey-index-9 = <0x5f>;

		key_14 {
			key-device = "secure";
			key-name = "attestationkeybox";
			key-permit = "read", "write", "del";
			phandle = <0x64>;
		};

		key_2 {
			key-device = "secure";
			key-type = "sha1";
			key-name = "hdcp";
			key-permit = "read", "write", "del";
			phandle = <0x58>;
		};

		key_12 {
			key-device = "secure";
			key-name = "prpubkeybox";
			key-permit = "read", "write", "del";
			phandle = <0x62>;
		};

		key_0 {
			key-device = "normal";
			key-name = "usid";
			key-permit = "read", "write", "del";
			phandle = <0x56>;
		};

		key_9 {
			key-device = "normal";
			key-name = "deviceid";
			key-permit = "read", "write", "del";
			phandle = <0x5f>;
		};

		key_10 {
			key-device = "secure";
			key-name = "hdcp22_fw_private";
			key-permit = "read", "write", "del";
			phandle = <0x60>;
		};

		key_7 {
			key-device = "normal";
			key-name = "hdcp2_rx";
			key-permit = "read", "write", "del";
			phandle = <0x5d>;
		};

		key_17 {
			key-device = "normal";
			key-name = "f_serial";
			key-permit = "read", "write", "del";
			phandle = <0x67>;
		};

		key_5 {
			key-device = "normal";
			key-type = "mac";
			key-name = "mac_wifi";
			key-permit = "read", "write", "del";
			phandle = <0x5b>;
		};

		key_15 {
			key-device = "normal";
			key-name = "region_code";
			key-permit = "read", "write", "del";
			phandle = <0x65>;
		};

		key_3 {
			key-device = "efuse";
			key-name = "secure_boot_set";
			key-permit = "write";
			phandle = <0x59>;
		};

		key_13 {
			key-device = "secure";
			key-name = "prprivkeybox";
			key-permit = "read", "write", "del";
			phandle = <0x63>;
		};

		key_1 {
			key-device = "normal";
			key-name = "mac";
			key-permit = "read", "write", "del";
			phandle = <0x57>;
		};

		key_11 {
			key-device = "secure";
			key-name = "PlayReadykeybox25";
			key-permit = "read", "write", "del";
			phandle = <0x61>;
		};

		key_8 {
			key-device = "secure";
			key-name = "widevinekeybox";
			key-permit = "read", "write", "del";
			phandle = <0x5e>;
		};

		key_6 {
			key-device = "normal";
			key-name = "hdcp2_tx";
			key-permit = "read", "write", "del";
			phandle = <0x5c>;
		};

		key_16 {
			key-device = "secure";
			key-name = "netflix_mgkid";
			key-permit = "read", "write", "del";
			phandle = <0x66>;
		};

		key_4 {
			key-device = "normal";
			key-type = "mac";
			key-name = "mac_bt";
			key-permit = "read", "write", "del";
			phandle = <0x5a>;
		};
	};

	vdin0 {
		compatible = "amlogic, vdin";
		dev_name = "vdin0";
		flag_cma = <0x00>;
		status = "disabled";
		interrupts = <0x00 0x53 0x01>;
		phandle = <0xe4>;
		rdma-irq = <0x02>;
		vdin_id = <0x00>;
		reserve-iomap = "true";
	};

	firmware {

		android {
			compatible = "android,firmware";

			fstab {
				compatible = "android,fstab";

				system {
					compatible = "android,system";
					dev = "/dev/block/system";
					type = "ext4";
					fsmgr_flags = "wait,slotselect";
					mnt_flags = "ro,barrier=1,inode_readahead_blks=8";
				};
			};

			vbmeta {
				compatible = "android,vbmeta";
				parts = "boot,system";
				by_name_prefix = "/dev/block";
			};
		};
	};

	pinctrl@ff800014 {
		compatible = "amlogic,meson-g12a-aobus-pinctrl";
		ranges;
		#address-cells = <0x02>;
		#size-cells = <0x02>;
		phandle = <0x7b>;

		pwm_ao_b {
			phandle = <0x82>;

			mux {
				groups = "pwm_ao_b";
				function = "pwm_ao_b";
			};
		};

		remote_pin {
			phandle = <0x8a>;

			mux {
				groups = "remote_input_ao";
				function = "remote_input_ao";
			};
		};

		ao_i2c_pins1 {
			phandle = <0x7e>;

			mux {
				drive-strength = <0x02>;
				groups = "i2c_ao_sck", "i2c_ao_sda";
				function = "i2c_ao";
			};
		};

		spdifout {
			phandle = <0x8b>;

			mux {
				groups = "spdif_out_ao";
				function = "spdif_out_ao";
			};
		};

		ao_cecb {
			phandle = <0x89>;

			mux {
				groups = "cec_ao_b";
				function = "cec_ao";
			};
		};

		sd_to_ao_uart_clr_pins {
			phandle = <0x7c>;

			mux {
				groups = "GPIOAO_0", "GPIOAO_1";
				function = "gpio_aobus";
			};
		};

		pwm_ao_d_pins2 {
			phandle = <0x87>;

			mux {
				groups = "pwm_ao_d_10";
				function = "pwm_ao_d";
			};
		};

		pwm_ao_c_pins1 {
			phandle = <0x83>;

			mux {
				groups = "pwm_ao_c_4";
				function = "pwm_ao_c";
			};
		};

		jtag_apao_pin {
			phandle = <0x17>;

			mux {
				groups = "jtag_a_tdi", "jtag_a_tdo", "jtag_a_clk", "jtag_a_tms";
				function = "jtag_a";
			};
		};

		pwm_ao_c_hiz {
			phandle = <0x85>;

			mux {
				groups = "pwm_ao_c_hiz_4";
				function = "pwm_ao_c";
			};
		};

		ao_i2c_pins2 {
			phandle = <0x7f>;

			mux {
				drive-strength = <0x02>;
				groups = "i2c_ao_sck_e", "i2c_ao_sda_e";
				function = "i2c_ao";
			};
		};

		ao_i2c_slave_pins {
			phandle = <0x1e>;

			mux {
				groups = "i2c_ao_slave_sck", "i2c_ao_slave_sda";
				function = "i2c_ao_slave";
			};
		};

		ao_uart {
			phandle = <0x1f>;

			mux {
				groups = "uart_ao_tx_a", "uart_ao_rx_a";
				function = "uart_ao_a";
			};
		};

		pwm_ao_a {
			phandle = <0x80>;

			mux {
				groups = "pwm_ao_a";
				function = "pwm_ao_a";
			};
		};

		ao-bank@ff800014 {
			reg-names = "mux", "gpio", "drive-strength";
			gpio-controller;
			phandle = <0x4a>;
			reg = <0x00 0xff800014 0x00 0x08 0x00 0xff800024 0x00 0x14 0x00 0xff80001c 0x00 0x08>;
			#gpio-cells = <0x02>;
		};

		pwm_ao_d_pins3 {
			phandle = <0x72>;

			mux {
				groups = "pwm_ao_d_e";
				function = "pwm_ao_d";
			};
		};

		ao_b_uart {
			phandle = <0x20>;

			mux {
				groups = "uart_ao_tx_b_2", "uart_ao_rx_b_3";
				function = "uart_ao_b";
			};
		};

		sd_to_ao_uart_pins {
			phandle = <0x7d>;

			mux {
				groups = "uart_ao_tx_a", "uart_ao_rx_a";
				function = "uart_ao_a";
				input-enable;
				bias-pull-up;
			};
		};

		ao_ceca {
			phandle = <0x88>;

			mux {
				groups = "cec_ao_a";
				function = "cec_ao";
			};
		};

		pwm_ao_d_pins1 {
			phandle = <0x86>;

			mux {
				groups = "pwm_ao_d_5";
				function = "pwm_ao_d";
			};
		};

		irblaster_pin {
			phandle = <0x21>;

			mux {
				groups = "remote_out_ao";
				function = "remote_out_ao";
			};
		};

		pwm_ao_c_pins2 {
			phandle = <0x84>;

			mux {
				groups = "pwm_ao_c_6";
				function = "pwm_ao_c";
			};
		};

		pwm_ao_a_hiz {
			phandle = <0x81>;

			mux {
				groups = "pwm_ao_a_hiz";
				function = "pwm_ao_a";
			};
		};

		spdifout_a_mute {
			phandle = <0x8c>;

			mux {
				groups = "GPIOAO_10";
				function = "gpio_aobus";
			};
		};
	};

	cpu_opp_table2 {
		compatible = "operating-points-v2";
		phandle = <0x0f>;
		opp-shared;

		opp06 {
			opp-microvolt = <0xb9ca8>;
			opp-hz = <0x00 0x5353c980>;
		};

		opp04 {
			opp-microvolt = <0xb2778>;
			opp-hz = <0x00 0x3b9aca00>;
		};

		opp12 {
			opp-microvolt = <0xf6d38>;
			opp-hz = <0x00 0x7829b800>;
		};

		opp02 {
			opp-microvolt = <0xb2778>;
			opp-hz = <0x00 0x1dcd6500>;
		};

		opp10 {
			opp-microvolt = <0xef808>;
			opp-hz = <0x00 0x6b49d200>;
		};

		opp00 {
			opp-microvolt = <0xb2778>;
			opp-hz = <0x00 0x5f5e100>;
		};

		opp09 {
			opp-microvolt = <0xd2348>;
			opp-hz = <0x00 0x6590fa00>;
		};

		opp07 {
			opp-microvolt = <0xc11d8>;
			opp-hz = <0x00 0x5a1f4a00>;
		};

		opp05 {
			opp-microvolt = <0xb2778>;
			opp-hz = <0x00 0x47868c00>;
		};

		opp13 {
			opp-microvolt = <0xf6d38>;
			opp-hz = <0x00 0x7d2b7500>;
		};

		opp03 {
			opp-microvolt = <0xb2778>;
			opp-hz = <0x00 0x27c19cc0>;
		};

		opp11 {
			opp-microvolt = <0xf1f18>;
			opp-hz = <0x00 0x71b9c500>;
		};

		opp01 {
			opp-microvolt = <0xb2778>;
			opp-hz = <0x00 0xee6b280>;
		};

		opp08 {
			opp-microvolt = <0xcae18>;
			opp-hz = <0x00 0x5fd82200>;
		};
	};

	partitions {
		part-7 = <0x41>;
		parts = <0x0c>;
		part-5 = <0x3f>;
		part-3 = <0x3d>;
		part-1 = <0x3b>;
		part-10 = <0x44>;
		part-8 = <0x42>;
		part-6 = <0x40>;
		phandle = <0xff>;
		part-4 = <0x3e>;
		part-2 = <0x3c>;
		part-0 = <0x3a>;
		part-11 = <0x45>;
		part-9 = <0x43>;

		logo {
			pname = "logo";
			mask = <0x01>;
			size = <0x00 0x800000>;
			phandle = <0x3a>;
		};

		dtbo_a {
			pname = "dtbo_a";
			mask = <0x01>;
			size = <0x00 0x400000>;
			phandle = <0x3b>;
		};

		misc {
			pname = "misc";
			mask = <0x01>;
			size = <0x00 0x800000>;
			phandle = <0x43>;
		};

		system_b {
			pname = "system_b";
			mask = <0x01>;
			size = <0x00 0x2040b000>;
			phandle = <0x42>;
		};

		vbmeta_a {
			pname = "vbmeta_a";
			mask = <0x01>;
			size = <0x00 0x100000>;
			phandle = <0x3d>;
		};

		boot_b {
			pname = "boot_b";
			mask = <0x01>;
			size = <0x00 0x1000000>;
			phandle = <0x40>;
		};

		dtbo_b {
			pname = "dtbo_b";
			mask = <0x01>;
			size = <0x00 0x400000>;
			phandle = <0x3c>;
		};

		settings {
			pname = "settings";
			mask = <0x01>;
			size = <0x00 0x10000000>;
			phandle = <0x44>;
		};

		data {
			pname = "data";
			mask = <0x04>;
			size = <0xffffffff 0xffffffff>;
			phandle = <0x45>;
		};

		system_a {
			pname = "system_a";
			mask = <0x01>;
			size = <0x00 0x2040b000>;
			phandle = <0x41>;
		};

		vbmeta_b {
			pname = "vbmeta_b";
			mask = <0x01>;
			size = <0x00 0x100000>;
			phandle = <0x3e>;
		};

		boot_a {
			pname = "boot_a";
			mask = <0x01>;
			size = <0x00 0x1000000>;
			phandle = <0x3f>;
		};
	};

	xtal-clk {
		compatible = "fixed-clock";
		#clock-cells = <0x00>;
		phandle = <0x16>;
		clock-output-names = "xtal";
		clock-frequency = <0x16e3600>;
	};

	lcd {
		compatible = "amlogic, lcd-g12a";
		clocks = <0x02 0x24 0x02 0x31 0x02 0x9a 0x02 0x5d 0x02 0x5f 0x02 0x07>;
		mode = "tablet";
		clock-names = "dsi_host_gate", "dsi_phy_gate", "dsi_meas", "encl_top_gate", "encl_int_gate", "gp0_pll";
		pinctrl_version = <0x02>;
		key_valid = <0x00>;
		status = "okay";
		interrupts = <0x00 0x03 0x01 0x00 0x38 0x01>;
		phandle = <0x100>;
		reg = <0x00 0xffd07000 0x00 0x400 0x00 0xff644000 0x00 0x200>;
		lcd_cpu-gpios = <0x15 0x06 0x00>;
		lcd_cpu_gpio_names = "GPIOZ_5";
		interrupt-names = "vsync", "vsync2";

		lcd_1 {
			backlight_index = <0x00>;
			dsi_init_off = <0xff 0x00>;
			mipi_attr = <0x04 0x168 0x00 0x01 0x00 0x02 0x00 0x00>;
			interface = "mipi";
			clk_attr = <0x00 0x00 0x01 0x2a33390>;
			model_name = "TV070WSM";
			basic_setting = <0x258 0x400 0x2bc 0x41d 0x08 0x5f 0xa3>;
			power_on_step = <0x00 0x01 0x00 0xc8 0x02 0x00 0x00 0x00 0xff 0x00 0x00 0x00>;
			power_off_step = <0x02 0x00 0x00 0x00 0x00 0x00 0x00 0x14 0x00 0x01 0x01 0x64 0xff 0x00 0x00 0x00>;
			lcd_timing = <0x18 0x24 0x00 0x02 0x08 0x00>;
			extern_init = <0x01>;
			dsi_init_on = <0xff 0x0a 0xf0 0x03 0x00 0x01 0x1e 0xf0 0x03 0x00 0x00 0x0a 0xf0 0x03 0x00 0x01 0x1e 0xfc 0x02 0x04 0x03 0xff 0x00>;
		};

		lcd_8 {
			backlight_index = <0x00>;
			dsi_init_off = <0x05 0x01 0x28 0xfd 0x01 0x0a 0x05 0x01 0x10 0xff 0xff>;
			mipi_attr = <0x02 0x2a0 0x00 0x01 0x00 0x02 0x01 0x00>;
			interface = "mipi";
			clk_attr = <0x00 0x00 0x01 0x1a9feb0>;
			model_name = "ST7701S";
			basic_setting = <0x1e0 0x320 0x226 0x34e 0x10 0x34 0x56>;
			power_on_step = <0x00 0x00 0x01 0x01 0x00 0x00 0x00 0x0a 0x00 0x00 0x01 0x78 0x02 0x00 0x00 0xc8 0xff 0x00 0x00 0x00>;
			power_off_step = <0x02 0x00 0x00 0x96 0x00 0x00 0x00 0x78 0xff 0x00 0x00 0x00>;
			lcd_timing = <0x0a 0x1e 0x00 0x06 0x14 0x00>;
			extern_init = <0x07>;
			dsi_init_on = <0x05 0x01 0x11 0xfd 0x01 0x78 0x05 0x01 0x29 0xff 0xff>;
		};

		lcd_6 {
			backlight_index = <0x00>;
			dsi_init_off = <0xff 0x00>;
			mipi_attr = <0x04 0x190 0x00 0x01 0x00 0x02 0x00 0x00>;
			interface = "mipi";
			clk_attr = <0x00 0x00 0x01 0x2f24d90>;
			model_name = "P070ACB_FT";
			basic_setting = <0x258 0x400 0x302 0x42e 0x08 0x03 0x05>;
			power_on_step = <0x00 0x01 0x00 0xc8 0x02 0x00 0x00 0x00 0xff 0x00 0x00 0x00>;
			power_off_step = <0x02 0x00 0x00 0x00 0x00 0x00 0x00 0x14 0x00 0x01 0x01 0x64 0xff 0x00 0x00 0x00>;
			lcd_timing = <0x0a 0x50 0x00 0x06 0x14 0x00>;
			extern_init = <0x05>;
			dsi_init_on = <0xff 0x0a 0xf0 0x03 0x00 0x01 0x1e 0xf0 0x03 0x00 0x00 0x0a 0xf0 0x03 0x00 0x01 0x1e 0xfc 0x02 0x04 0x03 0xff 0x00>;
		};

		lcd_4 {
			backlight_index = <0x00>;
			dsi_init_off = <0x05 0x01 0x28 0xfd 0x01 0x0a 0x05 0x01 0x10 0xfd 0x01 0x0a 0xff 0x00>;
			mipi_attr = <0x04 0x12c 0x00 0x01 0x00 0x02 0x01 0x00>;
			interface = "mipi";
			clk_attr = <0x00 0x00 0x01 0x2d0fa50>;
			model_name = "TL070WSH27";
			basic_setting = <0x400 0x258 0x4e2 0x276 0x08 0x9a 0x56>;
			power_on_step = <0x00 0x01 0x00 0x64 0x00 0x00 0x00 0x0a 0x00 0x00 0x01 0x14 0x02 0x00 0x00 0x00 0xff 0x00 0x00 0x00>;
			power_off_step = <0x02 0x00 0x00 0x32 0x00 0x00 0x00 0x0a 0x00 0x01 0x01 0x64 0xff 0x00 0x00 0x00>;
			lcd_timing = <0x50 0x64 0x00 0x05 0x14 0x00>;
			extern_init = <0xff>;
			dsi_init_on = <0x05 0x01 0x11 0xfd 0x01 0x14 0x05 0x01 0x29 0xfd 0x01 0x14 0xff 0x00>;
		};

		lcd_2 {
			backlight_index = <0x00>;
			dsi_init_off = <0xff 0x00>;
			mipi_attr = <0x04 0x190 0x00 0x01 0x00 0x02 0x00 0x00>;
			interface = "mipi";
			clk_attr = <0x00 0x00 0x01 0x2e755c0>;
			model_name = "P070ACB";
			basic_setting = <0x258 0x400 0x2a8 0x4aa 0x08 0x03 0x05>;
			power_on_step = <0x00 0x01 0x00 0xc8 0x02 0x00 0x00 0x00 0xff 0x00 0x00 0x00>;
			power_off_step = <0x02 0x00 0x00 0x00 0x00 0x00 0x00 0x14 0x00 0x01 0x01 0x64 0xff 0x00 0x00 0x00>;
			lcd_timing = <0x18 0x24 0x00 0x0a 0x50 0x00>;
			extern_init = <0x02>;
			dsi_init_on = <0xff 0x0a 0xf0 0x03 0x00 0x01 0x1e 0xf0 0x03 0x00 0x00 0x0a 0xf0 0x03 0x00 0x01 0x1e 0xfc 0x02 0x04 0x03 0xff 0x00>;
		};

		lcd_0 {
			backlight_index = <0x00>;
			dsi_init_off = <0x05 0x01 0x28 0xfd 0x01 0x0a 0x05 0x01 0x10 0xfd 0x01 0x0a 0xff 0x00>;
			mipi_attr = <0x04 0x226 0x00 0x01 0x00 0x02 0x01 0x00>;
			interface = "mipi";
			clk_attr = <0x00 0x00 0x01 0x3dd6dc0>;
			model_name = "B080XAN01";
			basic_setting = <0x300 0x400 0x3b4 0x474 0x08 0x77 0x9f>;
			power_on_step = <0x00 0x01 0x00 0x64 0x00 0x00 0x00 0x0a 0x00 0x00 0x01 0x14 0x02 0x00 0x00 0x00 0xff 0x00 0x00 0x00>;
			power_off_step = <0x02 0x00 0x00 0x32 0x00 0x00 0x00 0x0a 0x00 0x01 0x01 0x64 0xff 0x00 0x00 0x00>;
			lcd_timing = <0x40 0x38 0x00 0x32 0x1e 0x00>;
			extern_init = <0xff>;
			dsi_init_on = <0x05 0x01 0x11 0xfd 0x01 0x14 0x05 0x01 0x29 0xfd 0x01 0x14 0xff 0x00>;
		};

		lcd_7 {
			backlight_index = <0x00>;
			dsi_init_off = <0x05 0x01 0x28 0xfd 0x01 0x0a 0x05 0x01 0x10 0xff 0xff>;
			mipi_attr = <0x02 0x00 0x00 0x01 0x00 0x02 0x01 0x00>;
			interface = "mipi";
			clk_attr = <0x00 0x00 0x01 0x1e230a0>;
			model_name = "ILI9806E";
			basic_setting = <0x1e0 0x320 0x276 0x344 0x10 0x33 0x56>;
			power_on_step = <0x00 0x00 0x01 0x01 0x00 0x00 0x00 0x0a 0x00 0x00 0x01 0x78 0x02 0x00 0x00 0xc8 0xff 0x00 0x00 0x00>;
			power_off_step = <0x02 0x00 0x00 0x96 0x00 0x00 0x00 0x78 0xff 0x00 0x00 0x00>;
			lcd_timing = <0x0a 0x32 0x00 0x04 0x14 0x00>;
			extern_init = <0x06>;
			dsi_init_on = <0x05 0x01 0x11 0xfd 0x01 0x78 0x05 0x01 0x29 0xff 0xff>;
		};

		lcd_5 {
			backlight_index = <0x00>;
			dsi_init_off = <0xff 0x00>;
			mipi_attr = <0x04 0x168 0x00 0x01 0x00 0x02 0x00 0x00>;
			interface = "mipi";
			clk_attr = <0x00 0x00 0x01 0x2a33390>;
			model_name = "TV070WSM_FT";
			basic_setting = <0x258 0x400 0x2bc 0x41d 0x08 0x5f 0xa3>;
			power_on_step = <0x00 0x01 0x00 0xc8 0x02 0x00 0x00 0x00 0xff 0x00 0x00 0x00>;
			power_off_step = <0x02 0x00 0x00 0x00 0x00 0x00 0x00 0x14 0x00 0x01 0x01 0x64 0xff 0x00 0x00 0x00>;
			lcd_timing = <0x18 0x24 0x00 0x02 0x08 0x00>;
			extern_init = <0x04>;
			dsi_init_on = <0xff 0x0a 0xf0 0x03 0x00 0x01 0x1e 0xf0 0x03 0x00 0x00 0x0a 0xf0 0x03 0x00 0x01 0x1e 0xfc 0x02 0x04 0x03 0xff 0x00>;
		};

		lcd_3 {
			backlight_index = <0x00>;
			dsi_init_off = <0xff 0x00>;
			mipi_attr = <0x04 0x3c0 0x00 0x01 0x00 0x02 0x01 0x00>;
			interface = "mipi";
			clk_attr = <0x00 0x00 0x01 0x70a71c8>;
			model_name = "TL050FHV02CT";
			basic_setting = <0x438 0x780 0x465 0x834 0x08 0x41 0x77>;
			power_on_step = <0x00 0x01 0x00 0xc8 0x00 0x00 0x01 0x14 0x00 0x00 0x00 0x0a 0x00 0x00 0x01 0x14 0x02 0x00 0x00 0x00 0xff 0x00 0x00 0x00>;
			power_off_step = <0x02 0x00 0x00 0x00 0x00 0x00 0x00 0x14 0x00 0x01 0x01 0x64 0xff 0x00 0x00 0x00>;
			lcd_timing = <0x05 0x1e 0x00 0x2c 0x6c 0x00>;
			extern_init = <0x03>;
			dsi_init_on = <0xff 0x00>;
		};
	};

	vdac {
		compatible = "amlogic, vdac-g12a";
		status = "okay";
	};

	pwmao_d-regulator {
		compatible = "pwm-regulator";
		status = "okay";
		voltage-table = <0xf9830 0x00 0xf6d38 0x03 0xf4628 0x06 0xf1f18 0x0a 0xef808 0x0d 0xed0f8 0x10 0xea9e8 0x14 0xe82d8 0x17 0xe5bc8 0x1a 0xe34b8 0x1e 0xe0da8 0x21 0xde698 0x24 0xdbf88 0x28 0xd9878 0x2b 0xd7168 0x2e 0xd4a58 0x32 0xd2348 0x35 0xcfc38 0x38 0xcd528 0x3c 0xcae18 0x3f 0xc8708 0x43 0xc5ff8 0x46 0xc38e8 0x49 0xc11d8 0x4c 0xbeac8 0x50 0xbc3b8 0x53 0xb9ca8 0x56 0xb7598 0x5a 0xb4e88 0x5d 0xb2778 0x60 0xb0068 0x64>;
		phandle = <0x10>;
		regulator-min-microvolt = <0xb0068>;
		regulator-max-microvolt = <0xf9830>;
		max-duty-cycle = <0x4e2>;
		regulator-always-on;
		pwms = <0x38 0x01 0x4e2 0x00>;
		regulator-name = "vddcpu0";
	};

	aliases {
		i2c3 = "/soc/cbus@ffd00000/i2c@1c000";
		i2c1 = "/soc/cbus@ffd00000/i2c@1e000";
		tsensor0 = "/p_tsensor@ff634594";
		serial3 = "/serial@ffd22000";
		serial1 = "/serial@ffd24000";
		i2c4 = "/soc/aobus@ff800000/i2c@5000";
		i2c2 = "/soc/cbus@ffd00000/i2c@1d000";
		i2c0 = "/soc/cbus@ffd00000/i2c@1f000";
		tsensor1 = "/d_tsensor@ff800228";
		serial4 = "/soc/aobus@ff800000/serial@4000";
		serial2 = "/serial@ffd23000";
		serial0 = "/soc/aobus@ff800000/serial@3000";
	};

	chosen {
		bootargs = "init=/sbin/pre-init ramoops.pstore_en=1 ramoops.record_size=0x8000 ramoops.console_size=0x4000 rootfstype=ext4 console=ttyS0,115200n8 no_console_suspend earlycon=aml-uart,0xff803000 ro rootwait skip_initramfs root=/dev/mmcblk0p14 androidboot.slot_suffix=${active_slot} logo=osd0,loaded,0x1f800000 fb_width=480 fb_height=800 vout=panel,enable panel_type=lcd_8 frac_rate_policy=1 osd_reverse=0 video_reverse=0 reboot_mode_android=normal androidboot.selinux=enforcing androidboot.firstboot=0 androidboot.hardware=amlogic irq_check_en=0 jtag=disable uboot_version=v1.0-74-gfd61b37038 ";
		linux,initrd-start = <0x00 0x13e2c000>;
		linux,initrd-end = <0x00 0x13e2c800>;
	};

	rng {
		quality = [03 e8];
		compatible = "amlogic,meson-rng";
		status = "okay";
		#address-cells = <0x02>;
		#size-cells = <0x02>;
		reg = <0x00 0xff630218 0x00 0x04>;
	};

	bl_extern {
		compatible = "amlogic, bl_extern";
		i2c_bus = "i2c_bus_3";
		status = "disabled";

		extern_1 {
			type = <0x02>;
			index = <0x01>;
			dim_max_min = <0xff 0x0a>;
			extern_name = "mipi_lt070me05";
		};

		extern_0 {
			i2c_address = <0x2c>;
			type = <0x00>;
			index = <0x00>;
			dim_max_min = <0xff 0x0a>;
			extern_name = "i2c_lp8556";
		};
	};

	d_tsensor@ff800228 {
		compatible = "amlogic, r1p1-tsensor";
		clocks = <0x02 0xd6>;
		cal_d = <0x24c3>;
		#thermal-sensor-cells = <0x01>;
		clock-names = "ts_comp";
		cal_b = <0x1a8>;
		rtemp = <0x1c138>;
		status = "okay";
		interrupts = <0x00 0x24 0x00>;
		phandle = <0x34>;
		device_name = "meson-dthermal";
		reg = <0x00 0xff634c00 0x00 0x50 0x00 0xff800230 0x00 0x04>;
		cal_type = <0x01>;
		cal_c = <0xc57>;
		cal_a = <0x144>;
	};

	cvbsout {
		compatible = "amlogic, cvbsout-g12a";
		clocks = <0x02 0x55 0x02 0x4e 0x02 0x4f 0x02 0x57>;
		dev_name = "cvbsout";
		performance = <0x1bf0 0x09 0x1b56 0x333 0x1b12 0x8080 0x1b05 0xfd 0x1c59 0xf850 0xffff 0x00>;
		performance_revB_telecom = <0x1bf0 0x09 0x1b56 0x546 0x1b12 0x8080 0x1b05 0x09 0x1c59 0xf850 0xffff 0x00>;
		clock-names = "venci_top_gate", "venci_0_gate", "venci_1_gate", "vdac_clk_gate";
		status = "okay";
		performance_sarft = <0x1bf0 0x09 0x1b56 0x333 0x1b12 0x00 0x1b05 0x09 0x1c59 0xfc48 0xffff 0x00>;
		clk_path = <0x00>;
	};

	cpu_opp_table0 {
		compatible = "operating-points-v2";
		phandle = <0x0d>;
		opp-shared;

		opp06 {
			opp-microvolt = <0xb9ca8>;
			opp-hz = <0x00 0x5353c980>;
		};

		opp04 {
			opp-microvolt = <0xb2778>;
			opp-hz = <0x00 0x3b9aca00>;
		};

		opp02 {
			opp-microvolt = <0xb2778>;
			opp-hz = <0x00 0x1dcd6500>;
		};

		opp10 {
			opp-microvolt = <0xef808>;
			opp-hz = <0x00 0x6b49d200>;
		};

		opp00 {
			opp-microvolt = <0xb2778>;
			opp-hz = <0x00 0x5f5e100>;
		};

		opp09 {
			opp-microvolt = <0xd2348>;
			opp-hz = <0x00 0x6590fa00>;
		};

		opp07 {
			opp-microvolt = <0xc11d8>;
			opp-hz = <0x00 0x5a1f4a00>;
		};

		opp05 {
			opp-microvolt = <0xb2778>;
			opp-hz = <0x00 0x47868c00>;
		};

		opp03 {
			opp-microvolt = <0xb2778>;
			opp-hz = <0x00 0x27c19cc0>;
		};

		opp01 {
			opp-microvolt = <0xb2778>;
			opp-hz = <0x00 0xee6b280>;
		};

		opp08 {
			opp-microvolt = <0xcae18>;
			opp-hz = <0x00 0x5fd82200>;
		};
	};

	usb3phy@ffe09080 {
		gpios = <0x15 0x17 0x00>;
		compatible = "amlogic, amlogic-new-usb3-v2";
		clocks = <0x02 0x18>;
		usb2-phy-reg-size = <0x80>;
		usb2-phy-reg = <0xffe09000>;
		clock-names = "pcie_refpll";
		portnum = <0x01>;
		gpio-vbus-power = "GPIOH_6";
		status = "disabled";
		interrupts = <0x00 0x10 0x04>;
		phandle = <0x14>;
		phy-reg = <0xff646000>;
		reg = <0x00 0xffe09080 0x00 0x20>;
		otg = <0x01>;
		phy-reg-size = <0x2000>;
	};

	jtag {
		compatible = "amlogic, jtag";
		select = "disable";
		pinctrl-1 = <0x18>;
		status = "okay";
		pinctrl-0 = <0x17>;
		pinctrl-names = "jtag_apao_pins", "jtag_apee_pins";
	};

	thermal-zones {

		dram_thermal {
			thermal-sensors = <0x36>;
			polling-delay = <0x3a98>;
			polling-delay-passive = <0x3e8>;

			trips {

				dram_pswitchon {
					hysteresis = <0x3e8>;
					temperature = <0xea60>;
					type = "passive";
					phandle = <0xf7>;
				};

				dram_pcontrol {
					hysteresis = <0x1388>;
					temperature = <0x124f8>;
					type = "passive";
					phandle = <0xf8>;
				};

				dram_critical {
					hysteresis = <0x3e8>;
					temperature = <0x14c08>;
					type = "critical";
					phandle = <0xf9>;
				};
			};
		};

		ddr_thermal {
			thermal-sensors = <0x34 0x01>;
			polling-delay = <0x3e8>;
			polling-delay-passive = <0x64>;
			phandle = <0xef>;
			sustainable-power = <0x866>;

			trips {

				trip-point@3 {
					hysteresis = <0x3e8>;
					temperature = <0x1adb0>;
					type = "critical";
					phandle = <0xf3>;
				};

				trip-point@1 {
					hysteresis = <0x1388>;
					temperature = <0x124f8>;
					type = "passive";
					phandle = <0xf1>;
				};

				trip-point@2 {
					hysteresis = <0x1388>;
					temperature = <0x14c08>;
					type = "hot";
					phandle = <0xf2>;
				};

				trip-point@0 {
					hysteresis = <0x1388>;
					temperature = <0xea60>;
					type = "passive";
					phandle = <0xf0>;
				};
			};
		};

		pcb_thermal {
			thermal-sensors = <0x37>;
			polling-delay = <0x3a98>;
			polling-delay-passive = <0x3e8>;

			trips {

				pcb_pcontrol {
					hysteresis = <0x1388>;
					temperature = <0x124f8>;
					type = "passive";
					phandle = <0xfb>;
				};

				pcb_pswitchon {
					hysteresis = <0x3e8>;
					temperature = <0xea60>;
					type = "passive";
					phandle = <0xfa>;
				};

				pcb_critical {
					hysteresis = <0x3e8>;
					temperature = <0x14c08>;
					type = "critical";
					phandle = <0xfc>;
				};
			};
		};

		bluetooth_thermal {
			thermal-sensors = <0x35>;
			polling-delay = <0x3a98>;
			polling-delay-passive = <0x3e8>;

			trips {

				bt_pswitchon {
					hysteresis = <0x3e8>;
					temperature = <0xea60>;
					type = "passive";
					phandle = <0xf4>;
				};

				bt_pcontrol {
					hysteresis = <0x1388>;
					temperature = <0x124f8>;
					type = "passive";
					phandle = <0xf5>;
				};

				bt_critical {
					hysteresis = <0x3e8>;
					temperature = <0x14c08>;
					type = "critical";
					phandle = <0xf6>;
				};
			};
		};

		soc_thermal {
			thermal-sensors = <0x2e 0x00>;
			polling-delay = <0x3e8>;
			polling-delay-passive = <0x64>;
			phandle = <0xeb>;
			sustainable-power = <0x5b4>;

			trips {

				trip-point@3 {
					hysteresis = <0x3e8>;
					temperature = <0x1adb0>;
					type = "critical";
					phandle = <0xee>;
				};

				trip-point@1 {
					hysteresis = <0x1388>;
					temperature = <0x14c08>;
					type = "passive";
					phandle = <0x2f>;
				};

				trip-point@2 {
					hysteresis = <0x1388>;
					temperature = <0x17318>;
					type = "hot";
					phandle = <0xed>;
				};

				trip-point@0 {
					hysteresis = <0x1388>;
					temperature = <0xea60>;
					type = "passive";
					phandle = <0xec>;
				};
			};

			cooling-maps {

				cpufreq_cooling_map {
					trip = <0x2f>;
					contribution = <0x400>;
					cooling-device = <0x30 0x00 0x04>;
				};

				gpucore_cooling_map {
					trip = <0x2f>;
					contribution = <0x400>;
					cooling-device = <0x33 0x00 0x02>;
				};

				cpucore_cooling_map {
					trip = <0x2f>;
					contribution = <0x400>;
					cooling-device = <0x31 0x00 0x03>;
				};

				gpufreq_cooling_map {
					trip = <0x2f>;
					contribution = <0x400>;
					cooling-device = <0x32 0x00 0x04>;
				};
			};
		};
	};

	mhu@c883c400 {
		compatible = "amlogic, meson_mhu";
		#mbox-cells = <0x01>;
		interrupts = <0x00 0xd1 0x01 0x00 0xd2 0x01>;
		mbox-names = "cpu_to_scp_low", "cpu_to_scp_high";
		mboxes = <0x12 0x00 0x12 0x01>;
		phandle = <0x12>;
		reg = <0x00 0xff63c400 0x00 0x4c 0x00 0xfffe7000 0x00 0x800>;
	};

	usb2phy@ffe09000 {
		pll-setting-5 = <0x8000fff>;
		compatible = "amlogic, amlogic-new-usb2-v2";
		pll-setting-3 = <0xac5f49e5>;
		pll-setting-1 = <0x9400414>;
		pll-setting-8 = <0xe000c>;
		portnum = <0x02>;
		pll-setting-6 = <0x78000>;
		status = "okay";
		pll-setting-4 = <0xfe18>;
		phandle = <0x13>;
		pll-setting-2 = <0x927e0000>;
		reg = <0x00 0xffe09000 0x00 0x80 0x00 0xffd01008 0x00 0x100 0x00 0xff636000 0x00 0x2000 0x00 0xff63a000 0x00 0x2000>;
		pll-setting-7 = <0xe0004>;
	};

	p_tsensor@ff634594 {
		compatible = "amlogic, r1p1-tsensor";
		clocks = <0x02 0xd6>;
		cal_d = <0x24c3>;
		#thermal-sensor-cells = <0x01>;
		clock-names = "ts_comp";
		cal_b = <0x1a8>;
		rtemp = <0x1c138>;
		status = "okay";
		interrupts = <0x00 0x23 0x00>;
		phandle = <0x2e>;
		device_name = "meson-pthermal";
		reg = <0x00 0xff634800 0x00 0x50 0x00 0xff800268 0x00 0x04>;
		cal_type = <0x01>;
		cal_c = <0xc57>;
		cal_a = <0x144>;
	};

	rdma {
		compatible = "amlogic, meson, rdma";
		dev_name = "amlogic-rdma";
		status = "okay";
		interrupts = <0x00 0x59 0x01>;
		interrupt-names = "rdma";
	};

	lcd_extern {
		compatible = "amlogic, lcd_extern";
		i2c_bus = "i2c_bus_0";
		key_valid = <0x00>;
		status = "okay";

		extern_3 {
			cmd_size = <0xff>;
			type = <0x02>;
			status = "okay";
			init_off = <0x05 0x01 0x28 0xfd 0x01 0x0a 0x05 0x01 0x10 0xfd 0x01 0x96 0xff 0x00>;
			index = <0x03>;
			extern_name = "mipi_default";
			init_on = <0x29 0x06 0xf0 0x55 0xaa 0x52 0x08 0x03 0x29 0x0a 0x90 0x03 0x14 0x09 0x00 0x00 0x00 0x38 0x00 0x00 0x29 0x0a 0x91 0x00 0x00 0x00 0x00 0x00 0x00 0x00 0x00 0x00 0x29 0x0c 0x92 0x40 0x0b 0x0c 0x0d 0x0e 0x00 0x38 0x00 0x10 0x03 0x04 0x29 0x09 0x94 0x00 0x08 0x0b 0x03 0xd2 0x03 0xd3 0x0c 0x29 0x11 0x95 0x00 0x00 0x00 0x00 0x00 0x00 0x00 0x00 0x00 0x00 0x00 0x00 0x00 0x00 0x00 0x00 0x29 0x03 0x99 0x00 0x00 0x29 0x0c 0x9a 0x00 0x00 0x00 0x00 0x00 0x00 0x00 0x00 0x00 0x00 0x00 0x29 0x07 0x9b 0x01 0x38 0x00 0x00 0x00 0x00 0x29 0x03 0x9c 0x00 0x00 0x29 0x09 0x9d 0x10 0x10 0x10 0x10 0x10 0x10 0x00 0x00 0x29 0x03 0x9e 0x00 0x00 0x29 0x0b 0xa0 0x9f 0x1f 0x08 0x1f 0x0a 0x1f 0x00 0x1f 0x14 0x1f 0x29 0x0b 0xa1 0x15 0x1f 0x1f 0x1f 0x1f 0x1f 0x1f 0x1f 0x1f 0x1f 0x29 0x0b 0xa2 0x1f 0x1f 0x1f 0x1f 0x1f 0x1f 0x1f 0x1f 0x1f 0x1f 0x29 0x0b 0xa4 0x1f 0x1f 0x1f 0x1f 0x1f 0x1f 0x1f 0x1f 0x1f 0x1f 0x29 0x0b 0xa5 0x1f 0x1f 0x1f 0x1f 0x1f 0x1f 0x1f 0x1f 0x1f 0x15 0x29 0x0b 0xa6 0x1f 0x14 0x1f 0x01 0x1f 0x0b 0x1f 0x09 0x1f 0x1f 0x29 0x0b 0xa7 0x1f 0x1f 0x0b 0x1f 0x09 0x1f 0x01 0x1f 0x15 0x1f 0x29 0x0b 0xa8 0x14 0x1f 0x1f 0x1f 0x1f 0x1f 0x1f 0x1f 0x1f 0x1f 0x29 0x0b 0xa9 0x1f 0x1f 0x1f 0x1f 0x1f 0x1f 0x1f 0x1f 0x1f 0x1f 0x29 0x0b 0xab 0x1f 0x1f 0x1f 0x1f 0x1f 0x1f 0x1f 0x1f 0x1f 0x1f 0x29 0x0b 0xac 0x1f 0x1f 0x1f 0x1f 0x1f 0x1f 0x1f 0x1f 0x1f 0x14 0x29 0x0b 0xad 0x1f 0x15 0x1f 0x00 0x1f 0x08 0x1f 0x0a 0x1f 0x1f 0x29 0x06 0xf0 0x55 0xaa 0x52 0x08 0x00 0x29 0x04 0xbc 0x00 0x00 0x00 0x29 0x05 0xb8 0x01 0xaf 0x8f 0x8f 0x29 0x06 0xf0 0x55 0xaa 0x52 0x08 0x01 0x29 0x11 0xd1 0x00 0x00 0x00 0x09 0x00 0x1f 0x00 0x30 0x00 0x3f 0x00 0x5d 0x00 0x79 0x00 0xa7 0x29 0x11 0xd2 0x00 0xcf 0x01 0x12 0x01 0x49 0x01 0xa1 0x01 0xeb 0x01 0xed 0x02 0x2f 0x02 0x74 0x29 0x11 0xd3 0x02 0x9f 0x02 0xd5 0x02 0xfb 0x03 0x2c 0x03 0x4b 0x03 0x73 0x03 0x8c 0x03 0xa5 0x29 0x05 0xd4 0x03 0xc5 0x03 0xff 0x29 0x11 0xd5 0x00 0x00 0x00 0x09 0x00 0x1f 0x00 0x30 0x00 0x3f 0x00 0x5d 0x00 0x79 0x00 0xa7 0x29 0x11 0xd6 0x00 0xcf 0x01 0x12 0x01 0x49 0x01 0xa1 0x01 0xeb 0x01 0xed 0x02 0x2f 0x02 0x74 0x29 0x11 0xd7 0x02 0x9f 0x02 0xd5 0x02 0xfb 0x03 0x2c 0x03 0x4b 0x03 0x73 0x03 0x8c 0x03 0xa5 0x29 0x05 0xd8 0x03 0xc5 0x03 0xff 0x29 0x11 0xd9 0x00 0x00 0x00 0x09 0x00 0x1f 0x00 0x30 0x00 0x3f 0x00 0x5d 0x00 0x79 0x00 0xa7 0x29 0x11 0xdd 0x00 0xcf 0x01 0x12 0x01 0x49 0x01 0xa1 0x01 0xeb 0x01 0xed 0x02 0x2f 0x02 0x74 0x29 0x11 0xde 0x02 0x9f 0x02 0xd5 0x02 0xfb 0x03 0x2c 0x03 0x4b 0x03 0x73 0x03 0x8c 0x03 0xa5 0x29 0x05 0xdf 0x03 0xc5 0x03 0xff 0x29 0x11 0xe0 0x00 0x00 0x00 0x09 0x00 0x1f 0x00 0x30 0x00 0x3f 0x00 0x5d 0x00 0x79 0x00 0xa7 0x29 0x11 0xe1 0x00 0xcf 0x01 0x12 0x01 0x49 0x01 0xa1 0x01 0xeb 0x01 0xed 0x02 0x2f 0x02 0x74 0x29 0x11 0xe2 0x02 0x9f 0x02 0xd5 0x02 0xfb 0x03 0x2c 0x03 0x4b 0x03 0x73 0x03 0x8c 0x03 0xa5 0x29 0x05 0xe3 0x03 0xc5 0x03 0xff 0x29 0x11 0xe4 0x00 0x00 0x00 0x09 0x00 0x1f 0x00 0x30 0x00 0x3f 0x00 0x5d 0x00 0x79 0x00 0xa7 0x29 0x11 0xe5 0x00 0xcf 0x01 0x12 0x01 0x49 0x01 0xa1 0x01 0xeb 0x01 0xed 0x02 0x2f 0x02 0x74 0x29 0x11 0xe6 0x02 0x9f 0x02 0xd5 0x02 0xfb 0x03 0x2c 0x03 0x4b 0x03 0x73 0x03 0x8c 0x03 0xa5 0x29 0x05 0xe7 0x03 0xc5 0x03 0xff 0x29 0x11 0xe8 0x00 0x00 0x00 0x09 0x00 0x1f 0x00 0x30 0x00 0x3f 0x00 0x5d 0x00 0x79 0x00 0xa7 0x29 0x11 0xe9 0x00 0xcf 0x01 0x12 0x01 0x49 0x01 0xa1 0x01 0xeb 0x01 0xed 0x02 0x2f 0x02 0x74 0x29 0x11 0xea 0x02 0x9f 0x02 0xd5 0x02 0xfb 0x03 0x2c 0x03 0x4b 0x03 0x73 0x03 0x8c 0x03 0xa5 0x29 0x05 0xeb 0x03 0xc5 0x03 0xff 0x29 0x04 0xb0 0x05 0x05 0x05 0x29 0x04 0xb1 0x05 0x05 0x05 0x29 0x04 0xb3 0x10 0x10 0x10 0x29 0x04 0xb4 0x06 0x06 0x06 0x29 0x04 0xb6 0x44 0x44 0x44 0x29 0x04 0xb7 0x34 0x34 0x34 0x29 0x04 0xb8 0x34 0x34 0x34 0x29 0x04 0xb9 0x24 0x24 0x24 0x29 0x04 0xba 0x24 0x24 0x24 0x29 0x04 0xbc 0x00 0x70 0x00 0x29 0x04 0xbd 0x00 0x70 0x00 0x23 0x02 0xbe 0x50 0x23 0x02 0x35 0x00 0x13 0x01 0x11 0xfd 0x01 0xc8 0x13 0x01 0x29 0xfd 0x01 0xc8 0xff 0x00>;
		};

		extern_1 {
			cmd_size = <0xff>;
			type = <0x02>;
			status = "okay";
			init_off = <0x05 0x01 0x28 0xfd 0x01 0x0a 0x05 0x01 0x10 0xfd 0x01 0x96 0xff 0x00>;
			index = <0x01>;
			extern_name = "mipi_default";
			init_on = <0xfd 0x01 0x0a 0x15 0x02 0x62 0x01 0x39 0x05 0xff 0xaa 0x55 0x25 0x01 0x15 0x02 0xfc 0x08 0xfd 0x01 0x01 0x15 0x02 0xfc 0x00 0x39 0x05 0xff 0xaa 0x55 0x25 0x00 0xfd 0x01 0x14 0x39 0x06 0xf0 0x55 0xaa 0x52 0x08 0x00 0x39 0x03 0xb1 0x68 0x41 0x15 0x02 0xb5 0x88 0x15 0x02 0xb6 0x0f 0x39 0x05 0xb8 0x01 0x01 0x12 0x01 0x39 0x03 0xbb 0x11 0x11 0x39 0x03 0xbc 0x05 0x05 0x15 0x02 0xc7 0x03 0x39 0x06 0xbd 0x03 0x02 0x19 0x17 0x00 0x15 0x02 0xc8 0x80 0x39 0x06 0xf0 0x55 0xaa 0x52 0x08 0x01 0x39 0x03 0xb2 0x01 0x01 0x39 0x03 0xb3 0x28 0x28 0x39 0x03 0xb4 0x14 0x14 0x39 0x03 0xb8 0x05 0x05 0x39 0x03 0xb9 0x45 0x45 0x39 0x03 0xba 0x25 0x25 0x39 0x03 0xbc 0x88 0x00 0x39 0x03 0xbd 0x88 0x00 0x39 0x06 0xf0 0x55 0xaa 0x52 0x08 0x02 0x15 0x02 0xee 0x00 0x39 0x11 0xb0 0x00 0x4b 0x00 0x5c 0x00 0x79 0x00 0x94 0x00 0xa6 0x00 0xd8 0x00 0xf2 0x01 0x19 0x39 0x11 0xb1 0x01 0x39 0x01 0x77 0x01 0xa2 0x01 0xf2 0x02 0x32 0x02 0x34 0x02 0x6d 0x02 0xa2 0x39 0x11 0xb2 0x02 0xc7 0x02 0xf2 0x03 0x18 0x03 0x43 0x03 0x65 0x03 0x86 0x03 0x8f 0x03 0x94 0x39 0x05 0xb3 0x03 0x96 0x03 0x98 0x39 0x11 0xb4 0x00 0x84 0x00 0x91 0x00 0xa4 0x00 0xb6 0x00 0xca 0x00 0xe9 0x01 0x02 0x01 0x2a 0x39 0x11 0xb5 0x01 0x49 0x01 0x82 0x01 0xaf 0x01 0xf7 0x02 0x36 0x02 0x38 0x02 0x70 0x02 0xa6 0x39 0x11 0xb6 0x02 0xc8 0x02 0xf5 0x03 0x1a 0x03 0x43 0x03 0x62 0x03 0x82 0x03 0x8f 0x03 0x94 0x39 0x05 0xb7 0x03 0x96 0x03 0x98 0x39 0x11 0xb8 0x01 0x22 0x01 0x27 0x01 0x2e 0x01 0x38 0x01 0x40 0x01 0x53 0x01 0x60 0x01 0x7b 0x39 0x11 0xb9 0x01 0x8c 0x01 0xb5 0x01 0xd3 0x02 0x11 0x02 0x49 0x02 0x4a 0x02 0x7f 0x02 0xb1 0x39 0x11 0xba 0x02 0xd1 0x03 0x00 0x03 0x22 0x03 0x49 0x03 0x60 0x03 0x7a 0x03 0x8b 0x03 0x8f 0x39 0x05 0xbb 0x03 0x93 0x03 0x9a 0x39 0x11 0xbc 0x00 0x37 0x00 0x48 0x00 0x65 0x00 0x80 0x00 0x92 0x00 0xc4 0x00 0xde 0x01 0x05 0x39 0x11 0xbd 0x01 0x31 0x01 0x6f 0x01 0x9e 0x01 0xee 0x02 0x32 0x02 0x34 0x02 0x71 0x02 0xa7 0x39 0x11 0xbe 0x02 0xd3 0x02 0xfe 0x03 0x24 0x03 0x4f 0x03 0x71 0x03 0x92 0x03 0x9b 0x03 0xa0 0x39 0x05 0xbf 0x03 0xa6 0x03 0xa8 0x39 0x11 0xc0 0x00 0x70 0x00 0x7d 0x00 0x90 0x00 0xa4 0x00 0xb6 0x00 0xd5 0x00 0xee 0x01 0x16 0x39 0x11 0xc1 0x01 0x41 0x01 0x7a 0x01 0xab 0x01 0xf3 0x02 0x36 0x02 0x38 0x02 0x74 0x02 0xaa 0x39 0x11 0xc2 0x02 0xd4 0x03 0x01 0x03 0x26 0x03 0x4f 0x03 0x6e 0x03 0x8e 0x03 0x9b 0x03 0xa0 0x39 0x05 0xc3 0x03 0xa6 0x03 0xa8 0x39 0x11 0xc4 0x01 0x0e 0x01 0x13 0x01 0x1a 0x01 0x24 0x01 0x2c 0x01 0x3f 0x01 0x4c 0x01 0x67 0x39 0x11 0xc5 0x01 0x84 0x01 0xad 0x01 0xcf 0x02 0x0d 0x02 0x49 0x02 0x4a 0x02 0x83 0x02 0xb5 0x39 0x11 0xc6 0x02 0xdd 0x03 0x0c 0x03 0x2e 0x03 0x55 0x03 0x6b 0x03 0x86 0x03 0x97 0x03 0x9b 0x39 0x05 0xc7 0x03 0xa1 0x03 0xa8 0x39 0x06 0xf0 0x55 0xaa 0x52 0x08 0x04 0x39 0x06 0xb1 0x03 0x02 0x02 0x02 0x00 0x39 0x06 0xf0 0x55 0xaa 0x52 0x08 0x06 0x39 0x03 0xb0 0x11 0x11 0x39 0x03 0xb1 0x13 0x13 0x39 0x03 0xb2 0x03 0x03 0x39 0x03 0xb3 0x34 0x34 0x39 0x03 0xb4 0x34 0x34 0x39 0x03 0xb5 0x34 0x34 0x39 0x03 0xb6 0x34 0x34 0x39 0x03 0xb7 0x34 0x34 0x39 0x03 0xb8 0x34 0x34 0x39 0x03 0xb9 0x34 0x34 0x39 0x03 0xba 0x34 0x34 0x39 0x03 0xbb 0x34 0x34 0x39 0x03 0xbc 0x34 0x34 0x39 0x03 0xbd 0x34 0x34 0x39 0x03 0xbe 0x34 0x34 0x39 0x03 0xbf 0x34 0x34 0x39 0x03 0xc0 0x34 0x34 0x39 0x03 0xc1 0x02 0x02 0x39 0x03 0xc2 0x12 0x12 0x39 0x03 0xc3 0x10 0x10 0x39 0x03 0xe5 0x34 0x34 0x39 0x06 0xd8 0x00 0x00 0x00 0x00 0x00 0x39 0x06 0xd9 0x00 0x00 0x00 0x00 0x00 0x39 0x06 0xf0 0x55 0xaa 0x52 0x08 0x05 0x15 0x02 0xc0 0x03 0x15 0x02 0xc1 0x02 0x39 0x03 0xc8 0x01 0x20 0x15 0x02 0xe5 0x03 0x15 0x02 0xe6 0x03 0x15 0x02 0xe7 0x03 0x15 0x02 0xe8 0x03 0x15 0x02 0xe9 0x03 0x39 0x05 0xd1 0x03 0x00 0x3d 0x00 0x39 0x06 0xf0 0x55 0xaa 0x52 0x08 0x03 0x39 0x03 0xb0 0x11 0x00 0x39 0x03 0xb1 0x11 0x00 0x39 0x06 0xb2 0x03 0x00 0x00 0x00 0x00 0x39 0x06 0xb3 0x03 0x00 0x00 0x00 0x00 0x39 0x06 0xba 0x31 0x00 0x00 0x00 0x00 0x15 0x02 0x35 0x00 0x15 0x02 0x51 0xff 0x15 0x02 0x53 0x2c 0x15 0x02 0x55 0x03 0x05 0x01 0x11 0xfd 0x01 0x78 0x05 0x01 0x29 0xfd 0x01 0x82 0xff 0x00>;
		};

		extern_6 {
			cmd_size = <0xff>;
			type = <0x02>;
			status = "okay";
			init_off = <0x05 0x01 0x28 0xfd 0x01 0x0a 0x05 0x01 0x10 0xfd 0x01 0x1e 0xff 0xff>;
			index = <0x06>;
			extern_name = "mipi_ILI9806E";
			init_on = <0x39 0x06 0xff 0xff 0x98 0x06 0x04 0x01 0x15 0x02 0x08 0x10 0x15 0x02 0x20 0x00 0x15 0x02 0x21 0x01 0x15 0x02 0x30 0x02 0x15 0x02 0x31 0x02 0x15 0x02 0x60 0x07 0x15 0x02 0x61 0x06 0x15 0x02 0x62 0x06 0x15 0x02 0x63 0x04 0x15 0x02 0x40 0x18 0x15 0x02 0x41 0x33 0x15 0x02 0x42 0x12 0x15 0x02 0x43 0x89 0x15 0x02 0x44 0x86 0x15 0x02 0x46 0x55 0x15 0x02 0x47 0x55 0x15 0x02 0x45 0x14 0x15 0x02 0x50 0x50 0x15 0x02 0x51 0x50 0x15 0x02 0x52 0x00 0x15 0x02 0x53 0x38 0x15 0x02 0xa0 0x00 0x15 0x02 0xa1 0x09 0x15 0x02 0xa2 0x0c 0x15 0x02 0xa3 0x0f 0x15 0x02 0xa4 0x06 0x15 0x02 0xa5 0x09 0x15 0x02 0xa6 0x07 0x15 0x02 0xa7 0x16 0x15 0x02 0xa8 0x06 0x15 0x02 0xa9 0x09 0x15 0x02 0xaa 0x11 0x15 0x02 0xab 0x06 0x15 0x02 0xac 0x0e 0x15 0x02 0xad 0x19 0x15 0x02 0xae 0x0e 0x15 0x02 0xaf 0x00 0x15 0x02 0xc0 0x00 0x15 0x02 0xc1 0x09 0x15 0x02 0xc2 0x0c 0x15 0x02 0xc3 0x0f 0x15 0x02 0xc4 0x06 0x15 0x02 0xc5 0x09 0x15 0x02 0xc6 0x07 0x15 0x02 0xc7 0x16 0x15 0x02 0xc8 0x06 0x15 0x02 0xc9 0x09 0x15 0x02 0xca 0x11 0x15 0x02 0xcb 0x06 0x15 0x02 0xcc 0x0e 0x15 0x02 0xcd 0x19 0x15 0x02 0xce 0x0e 0x15 0x02 0xcf 0x00 0x39 0x06 0xff 0xff 0x98 0x06 0x04 0x06 0x15 0x02 0x00 0xa0 0x15 0x02 0x01 0x05 0x15 0x02 0x02 0x00 0x15 0x02 0x03 0x00 0x15 0x02 0x04 0x01 0x15 0x02 0x05 0x01 0x15 0x02 0x06 0x88 0x15 0x02 0x07 0x04 0x15 0x02 0x08 0x01 0x15 0x02 0x09 0x90 0x15 0x02 0x0a 0x04 0x15 0x02 0x0b 0x01 0x15 0x02 0x0c 0x01 0x15 0x02 0x0d 0x01 0x15 0x02 0x0e 0x00 0x15 0x02 0x0f 0x00 0x15 0x02 0x10 0x55 0x15 0x02 0x11 0x50 0x15 0x02 0x12 0x01 0x15 0x02 0x13 0x85 0x15 0x02 0x14 0x85 0x15 0x02 0x15 0xc0 0x15 0x02 0x16 0x0b 0x15 0x02 0x17 0x00 0x15 0x02 0x18 0x00 0x15 0x02 0x19 0x00 0x15 0x02 0x1a 0x00 0x15 0x02 0x1b 0x00 0x15 0x02 0x1c 0x00 0x15 0x02 0x1d 0x00 0x15 0x02 0x20 0x01 0x15 0x02 0x21 0x23 0x15 0x02 0x22 0x45 0x15 0x02 0x23 0x67 0x15 0x02 0x24 0x01 0x15 0x02 0x25 0x23 0x15 0x02 0x26 0x45 0x15 0x02 0x27 0x67 0x15 0x02 0x30 0x02 0x15 0x02 0x31 0x22 0x15 0x02 0x32 0x11 0x15 0x02 0x33 0xaa 0x15 0x02 0x34 0xbb 0x15 0x02 0x35 0x66 0x15 0x02 0x36 0x00 0x15 0x02 0x37 0x22 0x15 0x02 0x38 0x22 0x15 0x02 0x39 0x22 0x15 0x02 0x3a 0x22 0x15 0x02 0x3b 0x22 0x15 0x02 0x3c 0x22 0x15 0x02 0x3d 0x22 0x15 0x02 0x3e 0x22 0x15 0x02 0x3f 0x22 0x15 0x02 0x40 0x22 0x15 0x02 0x52 0x12 0x15 0x02 0x53 0x12 0x39 0x06 0xff 0xff 0x98 0x06 0x04 0x07 0x15 0x02 0x17 0x32 0x15 0x02 0x02 0x17 0x15 0x02 0x18 0x1d 0x15 0x02 0xe1 0x79 0x39 0x06 0xff 0xff 0x98 0x06 0x04 0x00 0x15 0x02 0x3a 0x70 0x05 0x01 0x11 0xfd 0x01 0x78 0x05 0x01 0x29 0xfd 0x01 0x19 0xff 0xff>;
		};

		extern_4 {
			cmd_size = <0xff>;
			type = <0x02>;
			status = "okay";
			init_off = <0x05 0x01 0x28 0xfd 0x01 0x0a 0x05 0x01 0x10 0xfd 0x01 0x96 0xff 0x00>;
			index = <0x04>;
			extern_name = "mipi_default";
			init_on = <0x23 0x02 0xe0 0x00 0x23 0x02 0xe1 0x93 0x23 0x02 0xe2 0x65 0x23 0x02 0xe3 0xf8 0x23 0x02 0xe0 0x01 0x23 0x02 0x00 0x00 0x23 0x02 0x01 0x90 0x23 0x02 0x03 0x00 0x23 0x02 0x04 0x90 0x23 0x02 0x17 0x00 0x23 0x02 0x18 0xb0 0x23 0x02 0x19 0x01 0x23 0x02 0x1a 0x00 0x23 0x02 0x1b 0xb0 0x23 0x02 0x1c 0x01 0x23 0x02 0x1f 0x3e 0x23 0x02 0x20 0x2f 0x23 0x02 0x21 0x2f 0x23 0x02 0x22 0x0e 0x23 0x02 0x37 0x69 0x23 0x02 0x38 0x05 0x23 0x02 0x39 0x00 0x23 0x02 0x3a 0x01 0x23 0x02 0x3c 0x90 0x23 0x02 0x3d 0xff 0x23 0x02 0x3e 0xff 0x23 0x02 0x3f 0xff 0x23 0x02 0x40 0x02 0x23 0x02 0x41 0x80 0x23 0x02 0x42 0x99 0x23 0x02 0x43 0x06 0x23 0x02 0x44 0x09 0x23 0x02 0x45 0x3c 0x23 0x02 0x4b 0x04 0x23 0x02 0x55 0x0f 0x23 0x02 0x56 0x01 0x23 0x02 0x57 0x89 0x23 0x02 0x58 0x0a 0x23 0x02 0x59 0x0a 0x23 0x02 0x5a 0x27 0x23 0x02 0x5b 0x15 0x23 0x02 0x5d 0x7c 0x23 0x02 0x5e 0x67 0x23 0x02 0x5f 0x58 0x23 0x02 0x60 0x4c 0x23 0x02 0x61 0x48 0x23 0x02 0x62 0x38 0x23 0x02 0x63 0x3c 0x23 0x02 0x64 0x24 0x23 0x02 0x65 0x3b 0x23 0x02 0x66 0x38 0x23 0x02 0x67 0x36 0x23 0x02 0x68 0x53 0x23 0x02 0x69 0x3f 0x23 0x02 0x6a 0x44 0x23 0x02 0x6b 0x35 0x23 0x02 0x6c 0x2e 0x23 0x02 0x6d 0x1f 0x23 0x02 0x6e 0x0c 0x23 0x02 0x6f 0x00 0x23 0x02 0x70 0x7c 0x23 0x02 0x71 0x67 0x23 0x02 0x72 0x58 0x23 0x02 0x73 0x4c 0x23 0x02 0x74 0x48 0x23 0x02 0x75 0x38 0x23 0x02 0x76 0x3c 0x23 0x02 0x77 0x24 0x23 0x02 0x78 0x3b 0x23 0x02 0x79 0x38 0x23 0x02 0x7a 0x36 0x23 0x02 0x7b 0x53 0x23 0x02 0x7c 0x3f 0x23 0x02 0x7d 0x44 0x23 0x02 0x7e 0x35 0x23 0x02 0x7f 0x2e 0x23 0x02 0x80 0x1f 0x23 0x02 0x81 0x0c 0x23 0x02 0x82 0x00 0x23 0x02 0xe0 0x02 0x23 0x02 0x00 0x45 0x23 0x02 0x01 0x45 0x23 0x02 0x02 0x47 0x23 0x02 0x03 0x47 0x23 0x02 0x04 0x41 0x23 0x02 0x05 0x41 0x23 0x02 0x06 0x1f 0x23 0x02 0x07 0x1f 0x23 0x02 0x08 0x1f 0x23 0x02 0x09 0x1f 0x23 0x02 0x0a 0x1f 0x23 0x02 0x0b 0x1f 0x23 0x02 0x0c 0x1f 0x23 0x02 0x0d 0x1d 0x23 0x02 0x0e 0x1d 0x23 0x02 0x0f 0x1d 0x23 0x02 0x10 0x1f 0x23 0x02 0x11 0x1f 0x23 0x02 0x12 0x1f 0x23 0x02 0x13 0x1f 0x23 0x02 0x14 0x1f 0x23 0x02 0x15 0x1f 0x23 0x02 0x16 0x44 0x23 0x02 0x17 0x44 0x23 0x02 0x18 0x46 0x23 0x02 0x19 0x46 0x23 0x02 0x1a 0x40 0x23 0x02 0x1b 0x40 0x23 0x02 0x1c 0x1f 0x23 0x02 0x1d 0x1f 0x23 0x02 0x1e 0x1f 0x23 0x02 0x1f 0x1f 0x23 0x02 0x20 0x1f 0x23 0x02 0x21 0x1f 0x23 0x02 0x22 0x1f 0x23 0x02 0x23 0x1d 0x23 0x02 0x24 0x1d 0x23 0x02 0x25 0x1d 0x23 0x02 0x26 0x1f 0x23 0x02 0x27 0x1f 0x23 0x02 0x28 0x1f 0x23 0x02 0x29 0x1f 0x23 0x02 0x2a 0x1f 0x23 0x02 0x2b 0x1f 0x23 0x02 0x58 0x40 0x23 0x02 0x59 0x00 0x23 0x02 0x5a 0x00 0x23 0x02 0x5b 0x10 0x23 0x02 0x5c 0x06 0x23 0x02 0x5d 0x20 0x23 0x02 0x5e 0x00 0x23 0x02 0x5f 0x00 0x23 0x02 0x61 0x00 0x23 0x02 0x62 0x00 0x23 0x02 0x63 0x7a 0x23 0x02 0x64 0x7a 0x23 0x02 0x65 0x00 0x23 0x02 0x66 0x00 0x23 0x02 0x67 0x32 0x23 0x02 0x68 0x08 0x23 0x02 0x69 0x7a 0x23 0x02 0x6a 0x7a 0x23 0x02 0x6b 0x00 0x23 0x02 0x6c 0x00 0x23 0x02 0x6d 0x04 0x23 0x02 0x6e 0x04 0x23 0x02 0x6f 0x88 0x23 0x02 0x70 0x00 0x23 0x02 0x71 0x00 0x23 0x02 0x72 0x06 0x23 0x02 0x73 0x7b 0x23 0x02 0x74 0x00 0x23 0x02 0x75 0x07 0x23 0x02 0x76 0x00 0x23 0x02 0x77 0x5d 0x23 0x02 0x78 0x17 0x23 0x02 0x79 0x1f 0x23 0x02 0x7a 0x00 0x23 0x02 0x7b 0x00 0x23 0x02 0x7c 0x00 0x23 0x02 0x7d 0x03 0x23 0x02 0x7e 0x7b 0x23 0x02 0xe0 0x03 0x23 0x02 0xaf 0x20 0x23 0x02 0xe0 0x04 0x23 0x02 0x09 0x11 0x23 0x02 0x0e 0x48 0x23 0x02 0x2b 0x2b 0x23 0x02 0x2e 0x44 0x23 0x02 0x41 0xff 0x23 0x02 0xe0 0x00 0x23 0x02 0xe6 0x02 0x23 0x02 0xe7 0x0c 0x05 0x01 0x11 0xfd 0x01 0x78 0x23 0x02 0xe0 0x03 0x23 0x02 0x2b 0x01 0x23 0x02 0x2c 0x00 0x23 0x02 0x30 0x03 0x23 0x02 0x31 0xcc 0x23 0x02 0x32 0x03 0x23 0x02 0x33 0xc9 0x23 0x02 0x34 0x03 0x23 0x02 0x35 0xc0 0x23 0x02 0x36 0x03 0x23 0x02 0x37 0xb3 0x23 0x02 0x38 0x03 0x23 0x02 0x39 0xab 0x23 0x02 0x3a 0x03 0x23 0x02 0x3b 0x9d 0x23 0x02 0x3c 0x03 0x23 0x02 0x3d 0x8f 0x23 0x02 0x3e 0x03 0x23 0x02 0x3f 0x6d 0x23 0x02 0x40 0x03 0x23 0x02 0x41 0x51 0x23 0x02 0x42 0x03 0x23 0x02 0x43 0x17 0x23 0x02 0x44 0x02 0x23 0x02 0x45 0xd8 0x23 0x02 0x46 0x02 0x23 0x02 0x47 0x60 0x23 0x02 0x48 0x01 0x23 0x02 0x49 0xeb 0x23 0x02 0x4a 0x01 0x23 0x02 0x4b 0xe5 0x23 0x02 0x4c 0x01 0x23 0x02 0x4d 0x6c 0x23 0x02 0x4e 0x00 0x23 0x02 0x4f 0xf2 0x23 0x02 0x50 0x00 0x23 0x02 0x51 0xb4 0x23 0x02 0x52 0x00 0x23 0x02 0x53 0x74 0x23 0x02 0x54 0x00 0x23 0x02 0x55 0x54 0x23 0x02 0x56 0x00 0x23 0x02 0x57 0x34 0x23 0x02 0x58 0x00 0x23 0x02 0x59 0x26 0x23 0x02 0x5a 0x00 0x23 0x02 0x5b 0x18 0x23 0x02 0x5c 0x00 0x23 0x02 0x5d 0x11 0x23 0x02 0x5e 0x00 0x23 0x02 0x5f 0x0a 0x23 0x02 0x60 0x00 0x23 0x02 0x61 0x03 0x23 0x02 0x62 0x00 0x23 0x02 0x63 0x00 0x23 0x02 0x64 0x03 0x23 0x02 0x65 0x9e 0x23 0x02 0x66 0x03 0x23 0x02 0x67 0x9b 0x23 0x02 0x68 0x03 0x23 0x02 0x69 0x94 0x23 0x02 0x6a 0x03 0x23 0x02 0x6b 0x8c 0x23 0x02 0x6c 0x03 0x23 0x02 0x6d 0x85 0x23 0x02 0x6e 0x03 0x23 0x02 0x6f 0x76 0x23 0x02 0x70 0x03 0x23 0x02 0x71 0x67 0x23 0x02 0x72 0x03 0x23 0x02 0x73 0x4b 0x23 0x02 0x74 0x03 0x23 0x02 0x75 0x2e 0x23 0x02 0x76 0x02 0x23 0x02 0x77 0xf7 0x23 0x02 0x78 0x02 0x23 0x02 0x79 0xb8 0x23 0x02 0x7a 0x02 0x23 0x02 0x7b 0x46 0x23 0x02 0x7c 0x01 0x23 0x02 0x7d 0xd6 0x23 0x02 0x7e 0x01 0x23 0x02 0x7f 0xd0 0x23 0x02 0x80 0x01 0x23 0x02 0x81 0x5c 0x23 0x02 0x82 0x00 0x23 0x02 0x83 0xe7 0x23 0x02 0x84 0x00 0x23 0x02 0x85 0xaa 0x23 0x02 0x86 0x00 0x23 0x02 0x87 0x74 0x23 0x02 0x88 0x00 0x23 0x02 0x89 0x5a 0x23 0x02 0x8a 0x00 0x23 0x02 0x8b 0x3c 0x23 0x02 0x8c 0x00 0x23 0x02 0x8d 0x2c 0x23 0x02 0x8e 0x00 0x23 0x02 0x8f 0x1c 0x23 0x02 0x90 0x00 0x23 0x02 0x91 0x14 0x23 0x02 0x92 0x00 0x23 0x02 0x93 0x0c 0x23 0x02 0x94 0x00 0x23 0x02 0x95 0x04 0x23 0x02 0x96 0x00 0x23 0x02 0x97 0x00 0x23 0x02 0xe0 0x00 0x05 0x01 0x29 0xfd 0x01 0x05 0xff 0x00>;
		};

		extern_2 {
			cmd_size = <0xff>;
			type = <0x02>;
			status = "okay";
			init_off = <0x05 0x01 0x28 0xfd 0x01 0x0a 0x05 0x01 0x10 0xfd 0x01 0x96 0xff 0x00>;
			index = <0x02>;
			extern_name = "mipi_default";
			init_on = <0x29 0x05 0xff 0xaa 0x55 0x25 0x01 0x23 0x02 0xfc 0x08 0xfd 0x01 0x01 0x23 0x02 0xfc 0x00 0xfd 0x01 0x01 0x23 0x02 0x6f 0x21 0x23 0x02 0xf7 0x01 0xfd 0x01 0x01 0x23 0x02 0x6f 0x21 0x23 0x02 0xf7 0x00 0xfd 0x01 0x01 0x23 0x02 0x6f 0x1a 0x23 0x02 0xf7 0x05 0xfd 0x01 0x01 0x29 0x05 0xff 0xaa 0x55 0x25 0x00 0x29 0x06 0xf0 0x55 0xaa 0x52 0x08 0x00 0x29 0x03 0xb1 0x68 0x41 0x23 0x02 0xb5 0x88 0x29 0x06 0xbd 0x02 0xb0 0x0c 0x14 0x00 0x23 0x02 0xc8 0x80 0x29 0x06 0xf0 0x55 0xaa 0x52 0x08 0x01 0x29 0x03 0xb3 0x2d 0x2d 0x29 0x03 0xb4 0x19 0x19 0x23 0x02 0xb5 0x06 0x29 0x03 0xb9 0x36 0x36 0x29 0x03 0xba 0x26 0x26 0x29 0x03 0xbc 0xa8 0x01 0x29 0x03 0xbd 0xab 0x01 0x23 0x02 0xc0 0x0c 0x29 0x06 0xf0 0x55 0xaa 0x52 0x08 0x02 0x23 0x02 0xee 0x02 0x29 0x07 0xb0 0x00 0x50 0x00 0x52 0x00 0x73 0x23 0x02 0x6f 0x06 0x29 0x07 0xb0 0x00 0x8f 0x00 0xa5 0x00 0xca 0x23 0x02 0x6f 0x0c 0x29 0x05 0xb0 0x00 0xea 0x01 0x1b 0x29 0x07 0xb1 0x01 0x42 0x01 0x82 0x01 0xb3 0x23 0x02 0x6f 0x06 0x29 0x07 0xb1 0x02 0x00 0x02 0x41 0x02 0x42 0x23 0x02 0x6f 0x0c 0x29 0x05 0xb1 0x02 0x78 0x02 0xb5 0x29 0x07 0xb2 0x02 0xda 0x03 0x12 0x03 0x3a 0x23 0x02 0x6f 0x06 0x29 0x07 0xb2 0x03 0x6e 0x03 0x8d 0x03 0xb1 0x23 0x02 0x6f 0x0c 0x29 0x05 0xb2 0x03 0xca 0x03 0xe8 0x29 0x05 0xb3 0x03 0xf4 0x03 0xff 0x29 0x07 0xbc 0x00 0x05 0x00 0x52 0x00 0x73 0x23 0x02 0x6f 0x06 0x29 0x07 0xbc 0x00 0x8f 0x00 0xa5 0x00 0xca 0x23 0x02 0x6f 0x0c 0x29 0x05 0xbc 0x00 0xea 0x01 0x1b 0x29 0x07 0xbd 0x01 0x42 0x01 0x82 0x01 0xb3 0x23 0x02 0x6f 0x06 0x29 0x07 0xbd 0x02 0x00 0x02 0x41 0x02 0x42 0x23 0x02 0x6f 0x0c 0x29 0x05 0xbd 0x02 0x78 0x02 0xb5 0x29 0x07 0xbe 0x02 0xda 0x03 0x12 0x03 0x3a 0x23 0x02 0x6f 0x06 0x29 0x07 0xbe 0x03 0x6e 0x03 0x8d 0x03 0xb1 0x23 0x02 0x6f 0x0c 0x29 0x05 0xbe 0x03 0xca 0x03 0xe8 0x29 0x05 0xbf 0x03 0xf4 0x03 0xff 0x29 0x06 0xf0 0x55 0xaa 0x52 0x08 0x03 0x29 0x06 0xb2 0x05 0x00 0x00 0x00 0x00 0x29 0x06 0xb6 0x05 0x00 0x00 0x00 0x00 0x29 0x06 0xb7 0x05 0x00 0x00 0x00 0x00 0x29 0x06 0xba 0x57 0x00 0x00 0x00 0x00 0x29 0x06 0xbb 0x57 0x00 0x00 0x00 0x00 0x29 0x05 0xc0 0x00 0x34 0x00 0x00 0x29 0x05 0xc1 0x00 0x00 0x34 0x00 0x23 0x02 0xc4 0x40 0x29 0x06 0xf0 0x55 0xaa 0x52 0x08 0x05 0x29 0x03 0xb0 0x17 0x06 0x29 0x03 0xb1 0x17 0x06 0x29 0x03 0xb2 0x17 0x06 0x29 0x03 0xb3 0x17 0x06 0x29 0x03 0xb4 0x17 0x06 0x29 0x06 0xbd 0x03 0x01 0x03 0x03 0x01 0x23 0x02 0xc0 0x05 0x23 0x02 0xc4 0x82 0x23 0x02 0xc5 0xa2 0x29 0x03 0xc8 0x03 0x30 0x29 0x03 0xc9 0x03 0x31 0x29 0x04 0xcc 0x00 0x00 0x3c 0x29 0x04 0xcd 0x00 0x00 0x3c 0x29 0x06 0xd1 0x00 0x44 0x09 0x00 0x00 0x29 0x06 0xd2 0x00 0x04 0x0b 0x00 0x00 0x29 0x06 0xf0 0x55 0xaa 0x52 0x08 0x06 0x29 0x03 0xb0 0x0b 0x2d 0x29 0x03 0xb1 0x2d 0x09 0x29 0x03 0xb2 0x2a 0x29 0x29 0x03 0xb3 0x34 0x1b 0x29 0x03 0xb4 0x19 0x17 0x29 0x03 0xb5 0x15 0x13 0x29 0x03 0xb6 0x11 0x01 0x29 0x03 0xb7 0x34 0x34 0x29 0x03 0xb8 0x34 0x2d 0x29 0x03 0xb9 0x2d 0x34 0x29 0x03 0xba 0x2d 0x2d 0x29 0x03 0xbb 0x34 0x34 0x29 0x03 0xbc 0x34 0x34 0x29 0x03 0xbd 0x00 0x10 0x29 0x03 0xbe 0x12 0x14 0x29 0x03 0xbf 0x16 0x18 0x29 0x03 0xc0 0x1a 0x34 0x29 0x03 0xc1 0x29 0x2a 0x29 0x03 0xc2 0x08 0x2d 0x29 0x03 0xc3 0x2d 0x0a 0x29 0x03 0xc4 0x0a 0x2d 0x29 0x03 0xc5 0x2d 0x00 0x29 0x03 0xc6 0x2a 0x29 0x29 0x03 0xc7 0x34 0x14 0x29 0x03 0xc8 0x16 0x18 0x29 0x03 0xc9 0x1a 0x10 0x29 0x03 0xca 0x12 0x08 0x29 0x03 0xcb 0x34 0x34 0x29 0x03 0xcc 0x34 0x2d 0x29 0x03 0xcd 0x2d 0x34 0x29 0x03 0xce 0x2d 0x2d 0x29 0x03 0xcf 0x34 0x34 0x29 0x03 0xd0 0x34 0x34 0x29 0x03 0xd1 0x09 0x13 0x29 0x03 0xd2 0x11 0x1b 0x29 0x03 0xd3 0x19 0x17 0x29 0x03 0xd4 0x15 0x34 0x29 0x03 0xd5 0x29 0x2a 0x29 0x03 0xd6 0x01 0x2d 0x29 0x03 0xd7 0x2d 0x0b 0x29 0x06 0xd8 0x00 0x00 0x00 0x00 0x00 0x29 0x06 0xd9 0x00 0x00 0x00 0x00 0x00 0x29 0x03 0xe5 0x34 0x34 0x29 0x03 0xe6 0x34 0x34 0x23 0x02 0xe7 0x00 0x29 0x03 0xe8 0x34 0x34 0x29 0x03 0xe9 0x34 0x34 0x23 0x02 0xea 0x00 0x29 0x06 0xf0 0x55 0xaa 0x52 0x00 0x00 0x13 0x01 0x35 0x13 0x01 0x11 0xfd 0x01 0x78 0x13 0x01 0x29 0xfd 0x01 0x14 0xff 0x00>;
		};

		extern_0 {
			cmd_size = <0xff>;
			type = <0x02>;
			status = "okay";
			init_off = <0x05 0x01 0x28 0xfd 0x01 0x0a 0x05 0x01 0x10 0xfd 0x01 0x96 0xff 0x00>;
			index = <0x00>;
			extern_name = "mipi_default";
			init_on = <0xfd 0x01 0x0a 0x05 0x01 0x11 0xfd 0x01 0x78 0x05 0x01 0x29 0xff 0x00>;
		};

		extern_7 {
			cmd_size = <0xff>;
			type = <0x02>;
			status = "okay";
			init_off = <0x05 0x01 0x28 0xfd 0x01 0x0a 0x05 0x01 0x10 0xfd 0x01 0x1e 0xff 0xff>;
			index = <0x07>;
			extern_name = "mipi_ST7701";
			init_on = <0x39 0x06 0xff 0x77 0x01 0x00 0x00 0x13 0x39 0x02 0xef 0x08 0x39 0x06 0xff 0x77 0x01 0x00 0x00 0x10 0x39 0x03 0xc0 0x63 0x00 0x39 0x03 0xc1 0x0a 0x02 0x39 0x03 0xc2 0x31 0x07 0x39 0x02 0xcc 0x10 0x39 0x11 0xb0 0x0a 0x10 0x96 0x0e 0x11 0x06 0x06 0x0a 0x08 0x24 0x07 0x53 0x11 0x68 0xad 0xd1 0x39 0x11 0xb1 0x06 0x8d 0xd3 0x09 0x0d 0x04 0x04 0x07 0x07 0x23 0x05 0x15 0x14 0xa7 0xac 0x4f 0x39 0x06 0xff 0x77 0x01 0x00 0x00 0x11 0x39 0x02 0xb0 0x5d 0x39 0x02 0xb1 0x45 0x39 0x02 0xb2 0x82 0x39 0x02 0xb3 0x80 0x39 0x02 0xb5 0x45 0x39 0x02 0xb7 0x85 0x39 0x02 0xb8 0x21 0x39 0x03 0xb9 0x10 0x1f 0x39 0x02 0xbb 0x03 0x39 0x02 0xbc 0x3e 0x39 0x02 0xc1 0x78 0x39 0x02 0xc2 0x78 0x39 0x02 0xd0 0x88 0xfd 0x01 0x08 0x39 0x04 0xe0 0x00 0x00 0x02 0x39 0x0c 0xe1 0x04 0x00 0x00 0x00 0x05 0x00 0x00 0x00 0x00 0x20 0x20 0x39 0x0d 0xe2 0x00 0x00 0x00 0x00 0x00 0x00 0x00 0x00 0x00 0x00 0x00 0x00 0x39 0x05 0xe3 0x00 0x00 0x33 0x00 0x39 0x03 0xe4 0x22 0x00 0x39 0x11 0xe5 0x04 0x34 0x9a 0xa0 0x06 0x34 0x9a 0xa0 0x00 0x00 0x00 0x00 0x00 0x00 0x00 0x00 0x39 0x05 0xe6 0x00 0x00 0x33 0x00 0x39 0x03 0xe7 0x22 0x00 0x39 0x11 0xe8 0x05 0x34 0x9a 0xa0 0x07 0x34 0x9a 0xa0 0x00 0x00 0x00 0x00 0x00 0x00 0x00 0x00 0x39 0x08 0xeb 0x02 0x00 0x40 0x40 0x00 0x00 0x00 0x39 0x03 0xec 0x00 0x00 0x39 0x11 0xed 0xfa 0x45 0x0b 0xff 0xff 0xff 0xff 0xff 0xff 0xff 0xff 0xff 0xff 0xb0 0x54 0xaf 0x39 0x07 0xef 0x08 0x08 0x08 0x45 0x3f 0x54 0x39 0x06 0xff 0x77 0x01 0x00 0x00 0x13 0x39 0x03 0xe8 0x00 0x0e 0x39 0x06 0xff 0x77 0x01 0x00 0x00 0x00 0x39 0x02 0x11 0x00 0xfd 0x01 0x78 0x39 0x06 0xff 0x77 0x01 0x00 0x00 0x13 0x39 0x03 0xe8 0x00 0x0c 0xfd 0x01 0x02 0x39 0x03 0xe8 0x00 0x00 0x39 0x06 0xff 0x77 0x01 0x00 0x00 0x00 0x39 0x02 0x35 0x00 0x39 0x02 0x29 0x00 0xfd 0x01 0x0f 0xff 0xff>;
		};

		extern_5 {
			cmd_size = <0xff>;
			type = <0x02>;
			status = "okay";
			init_off = <0x05 0x01 0x28 0xfd 0x01 0x0a 0x05 0x01 0x10 0xfd 0x01 0x96 0xff 0x00>;
			index = <0x05>;
			extern_name = "mipi_default";
			init_on = <0x23 0x02 0xe0 0x00 0x23 0x02 0xe1 0x93 0x23 0x02 0xe2 0x65 0x23 0x02 0xe3 0xf8 0x23 0x02 0x80 0x03 0x23 0x02 0xe0 0x01 0x23 0x02 0x0c 0x74 0x23 0x02 0x17 0x00 0x23 0x02 0x18 0xef 0x23 0x02 0x19 0x00 0x23 0x02 0x1a 0x00 0x23 0x02 0x1b 0xef 0x23 0x02 0x1c 0x00 0x23 0x02 0x1f 0x70 0x23 0x02 0x20 0x2d 0x23 0x02 0x21 0x2d 0x23 0x02 0x22 0x7e 0x23 0x02 0x26 0xf3 0x23 0x02 0x37 0x09 0x23 0x02 0x38 0x04 0x23 0x02 0x39 0x00 0x23 0x02 0x3a 0x01 0x23 0x02 0x3c 0x90 0x23 0x02 0x3d 0xff 0x23 0x02 0x3e 0xff 0x23 0x02 0x3f 0xff 0x23 0x02 0x40 0x02 0x23 0x02 0x41 0x80 0x23 0x02 0x42 0x99 0x23 0x02 0x43 0x14 0x23 0x02 0x44 0x19 0x23 0x02 0x45 0x5a 0x23 0x02 0x4b 0x04 0x23 0x02 0x55 0x02 0x23 0x02 0x56 0x01 0x23 0x02 0x57 0x69 0x23 0x02 0x58 0x0a 0x23 0x02 0x59 0x0a 0x23 0x02 0x5a 0x2e 0x23 0x02 0x5b 0x19 0x23 0x02 0x5c 0x15 0x23 0x02 0x5d 0x77 0x23 0x02 0x5e 0x56 0x23 0x02 0x5f 0x45 0x23 0x02 0x60 0x38 0x23 0x02 0x61 0x35 0x23 0x02 0x62 0x27 0x23 0x02 0x63 0x2d 0x23 0x02 0x64 0x18 0x23 0x02 0x65 0x33 0x23 0x02 0x66 0x34 0x23 0x02 0x67 0x35 0x23 0x02 0x68 0x56 0x23 0x02 0x69 0x45 0x23 0x02 0x6a 0x4f 0x23 0x02 0x6b 0x42 0x23 0x02 0x6c 0x40 0x23 0x02 0x6d 0x34 0x23 0x02 0x6e 0x25 0x23 0x02 0x6f 0x02 0x23 0x02 0x70 0x77 0x23 0x02 0x71 0x56 0x23 0x02 0x72 0x45 0x23 0x02 0x73 0x38 0x23 0x02 0x74 0x35 0x23 0x02 0x75 0x27 0x23 0x02 0x76 0x2d 0x23 0x02 0x77 0x18 0x23 0x02 0x78 0x33 0x23 0x02 0x79 0x34 0x23 0x02 0x7a 0x35 0x23 0x02 0x7b 0x56 0x23 0x02 0x7c 0x45 0x23 0x02 0x7d 0x4f 0x23 0x02 0x7e 0x42 0x23 0x02 0x7f 0x40 0x23 0x02 0x80 0x34 0x23 0x02 0x81 0x25 0x23 0x02 0x82 0x02 0x23 0x02 0xe0 0x02 0x23 0x02 0x00 0x53 0x23 0x02 0x01 0x55 0x23 0x02 0x02 0x55 0x23 0x02 0x03 0x51 0x23 0x02 0x04 0x77 0x23 0x02 0x05 0x57 0x23 0x02 0x06 0x1f 0x23 0x02 0x07 0x4f 0x23 0x02 0x08 0x4d 0x23 0x02 0x09 0x1f 0x23 0x02 0x0a 0x4b 0x23 0x02 0x0b 0x49 0x23 0x02 0x0c 0x1f 0x23 0x02 0x0d 0x47 0x23 0x02 0x0e 0x45 0x23 0x02 0x0f 0x41 0x23 0x02 0x10 0x1f 0x23 0x02 0x11 0x1f 0x23 0x02 0x12 0x1f 0x23 0x02 0x13 0x55 0x23 0x02 0x14 0x1f 0x23 0x02 0x15 0x1f 0x23 0x02 0x16 0x52 0x23 0x02 0x17 0x55 0x23 0x02 0x18 0x55 0x23 0x02 0x19 0x50 0x23 0x02 0x1a 0x77 0x23 0x02 0x1b 0x57 0x23 0x02 0x1c 0x1f 0x23 0x02 0x1d 0x4e 0x23 0x02 0x1e 0x4c 0x23 0x02 0x1f 0x1f 0x23 0x02 0x20 0x4a 0x23 0x02 0x21 0x48 0x23 0x02 0x22 0x1f 0x23 0x02 0x23 0x46 0x23 0x02 0x24 0x44 0x23 0x02 0x25 0x40 0x23 0x02 0x26 0x1f 0x23 0x02 0x27 0x1f 0x23 0x02 0x28 0x1f 0x23 0x02 0x29 0x1f 0x23 0x02 0x2a 0x1f 0x23 0x02 0x2b 0x55 0x23 0x02 0x2c 0x12 0x23 0x02 0x2d 0x15 0x23 0x02 0x2e 0x15 0x23 0x02 0x2f 0x00 0x23 0x02 0x30 0x37 0x23 0x02 0x31 0x17 0x23 0x02 0x32 0x1f 0x23 0x02 0x33 0x08 0x23 0x02 0x34 0x0a 0x23 0x02 0x35 0x1f 0x23 0x02 0x36 0x0c 0x23 0x02 0x37 0x0e 0x23 0x02 0x38 0x1f 0x23 0x02 0x39 0x04 0x23 0x02 0x3a 0x06 0x23 0x02 0x3b 0x10 0x23 0x02 0x3c 0x1f 0x23 0x02 0x3d 0x1f 0x23 0x02 0x3e 0x1f 0x23 0x02 0x3f 0x15 0x23 0x02 0x40 0x1f 0x23 0x02 0x41 0x1f 0x23 0x02 0x42 0x13 0x23 0x02 0x43 0x15 0x23 0x02 0x44 0x15 0x23 0x02 0x45 0x01 0x23 0x02 0x46 0x37 0x23 0x02 0x47 0x17 0x23 0x02 0x48 0x1f 0x23 0x02 0x49 0x09 0x23 0x02 0x4a 0x0b 0x23 0x02 0x4b 0x1f 0x23 0x02 0x4c 0x0d 0x23 0x02 0x4d 0x0f 0x23 0x02 0x4e 0x1f 0x23 0x02 0x4f 0x05 0x23 0x02 0x50 0x07 0x23 0x02 0x51 0x11 0x23 0x02 0x52 0x1f 0x23 0x02 0x53 0x1f 0x23 0x02 0x54 0x1f 0x23 0x02 0x55 0x1f 0x23 0x02 0x56 0x1f 0x23 0x02 0x57 0x15 0x23 0x02 0x58 0x40 0x23 0x02 0x59 0x00 0x23 0x02 0x5a 0x00 0x23 0x02 0x5b 0x10 0x23 0x02 0x5c 0x14 0x23 0x02 0x5d 0x40 0x23 0x02 0x5e 0x01 0x23 0x02 0x5f 0x02 0x23 0x02 0x60 0x40 0x23 0x02 0x61 0x03 0x23 0x02 0x62 0x04 0x23 0x02 0x63 0x7a 0x23 0x02 0x64 0x7a 0x23 0x02 0x65 0x74 0x23 0x02 0x66 0x16 0x23 0x02 0x67 0xb4 0x23 0x02 0x68 0x16 0x23 0x02 0x69 0x7a 0x23 0x02 0x6a 0x7a 0x23 0x02 0x6b 0x0c 0x23 0x02 0x6c 0x00 0x23 0x02 0x6d 0x04 0x23 0x02 0x6e 0x04 0x23 0x02 0x6f 0x88 0x23 0x02 0x70 0x00 0x23 0x02 0x71 0x00 0x23 0x02 0x72 0x06 0x23 0x02 0x73 0x7b 0x23 0x02 0x74 0x00 0x23 0x02 0x75 0xbc 0x23 0x02 0x76 0x00 0x23 0x02 0x77 0x04 0x23 0x02 0x78 0x2c 0x23 0x02 0x79 0x00 0x23 0x02 0x7a 0x00 0x23 0x02 0x7b 0x00 0x23 0x02 0x7c 0x00 0x23 0x02 0x7d 0x03 0x23 0x02 0x7e 0x7b 0x23 0x02 0xe0 0x04 0x23 0x02 0x09 0x11 0x23 0x02 0x0e 0x48 0x23 0x02 0x2b 0x2b 0x23 0x02 0x2e 0x44 0x23 0x02 0xe0 0x00 0x23 0x02 0xe6 0x02 0x23 0x02 0xe7 0x0c 0x05 0x01 0x11 0xfd 0x01 0x78 0x05 0x01 0x29 0x05 0x01 0x35 0xfd 0x01 0x14 0xff 0x00>;
		};
	};

	drm-vpu@0xff900000 {
		compatible = "amlogic,meson-g12a-vpu";
		clocks = <0x02 0xc9>;
		reg-names = "base", "hhi", "dmc";
		dma-coherent;
		clock-names = "vpu_clkc";
		status = "okay";
		interrupts = <0x00 0x03 0x01 0x00 0x38 0x01>;
		memory-region = <0x2a>;
		phandle = <0x10c>;
		reg = <0x00 0xff900000 0x00 0x40000 0x00 0xff63c000 0x00 0x2000 0x00 0xff638000 0x00 0x2000>;
		interrupt-names = "viu-vsync", "viu2-vsync";

		port {
			#address-cells = <0x01>;
			#size-cells = <0x00>;
			phandle = <0x108>;

			endpoint@1 {
				remote-endpoint = <0x107>;
				phandle = <0x105>;
				reg = <0x01>;
			};

			endpoint@0 {
				remote-endpoint = <0x106>;
				phandle = <0x104>;
				reg = <0x00>;
			};
		};
	};

	serial@ffd23000 {
		compatible = "amlogic, meson-uart";
		clocks = <0x16 0x02 0x3c>;
		fifosize = <0x40>;
		clock-names = "clk_uart", "clk_gate";
		status = "disabled";
		interrupts = <0x00 0x4b 0x01>;
		phandle = <0xe2>;
		reg = <0x00 0xffd23000 0x00 0x18>;
		pinctrl-0 = <0x28>;
		pinctrl-names = "default";
	};

	pm {
		compatible = "amlogic, pm";
		status = "okay";
		phandle = <0x79>;
		device_name = "aml_pm";
		reg = <0x00 0xff8000a8 0x00 0x04 0x00 0xff80023c 0x00 0x04>;
	};

	timer {
		compatible = "arm,armv8-timer";
		interrupts = <0x01 0x0d 0xff08 0x01 0x0e 0xff08 0x01 0x0b 0xff08 0x01 0x0a 0xff08>;
	};

	ethernet@ff3f0000 {
		analog_val = <0x20200000 0xc000 0x23>;
		pll_val = <0x9c0040a 0x927e0000 0xac5f49e5>;
		compatible = "amlogic, g12a-eth-dwmac", "snps,dwmac";
		clocks = <0x02 0x38>;
		reg-names = "eth_base", "eth_cfg", "eth_pll";
		clock-names = "ethclk81";
		status = "disabled";
		interrupts = <0x00 0x08 0x01>;
		phandle = <0x7a>;
		reg = <0x00 0xff3f0000 0x00 0x10000 0x00 0xff634540 0x00 0x08 0x00 0xff64c000 0x00 0xa0>;
		interrupt-names = "macirq";
	};

	cpu_info {
		compatible = "amlogic, cpuinfo";
		cpuinfo_cmd = <0x82000044>;
		status = "okay";
	};

	thermal-sensor@3 {
		io-channels = <0x50 0x03>;
		compatible = "generic-adc-thermal";
		io-channel-names = "sensor-channel";
		#thermal-sensor-cells = <0x00>;
		temperature-lookup-table = <0x14c08 0x37e 0x13880 0x36e 0x124f8 0x35c 0x11170 0x347 0xfde8 0x32f 0xea60 0x315 0xd6d8 0x2f7 0xc350 0x2d6 0xafc8 0x2b2 0x9c40 0x28a 0x88b8 0x25f 0x7530 0x230 0x61a8 0x200 0x4e20 0x1ce 0x3a98 0x19b 0x2710 0x168 0x1388 0x137 0x00 0x109 0xffffec78 0xdd 0xffffd8f0 0xb6 0xffffc568 0x93 0xffffb1e0 0x75 0xffff9e58 0x5c 0xffff8ad0 0x46 0xffff7748 0x35 0xffff63c0 0x28>;
		phandle = <0x36>;
	};

	deinterlace {
		compatible = "amlogic, deinterlace";
		clocks = <0x02 0x9b 0x02 0x9c>;
		nr10bit-support = <0x01>;
		nrds-enable = <0x01>;
		flag_cma = <0x01>;
		clock-range = <0x14e 0x29b>;
		pps-enable = <0x01>;
		clock-names = "vpu_clkb_tmp_composite", "vpu_clkb_composite";
		post-wr-support = <0x01>;
		status = "okay";
		interrupts = <0x00 0x2e 0x01 0x00 0x28 0x01>;
		memory-region = <0x54>;
		interrupt-names = "pre_irq", "post_irq";
		buffer-size = <0x3e2c40>;
	};

	meson-cooldev@0 {
		compatible = "amlogic, meson-cooldev";
		status = "okay";
		phandle = <0xea>;
		device_name = "mcooldev";

		gpufreq_cool0 {
			phandle = <0x32>;
			#cooling-cells = <0x02>;
		};

		cpufreq_cool0 {
			phandle = <0x30>;
			#cooling-cells = <0x02>;
		};

		gpucore_cool0 {
			phandle = <0x33>;
			#cooling-cells = <0x02>;
		};

		cooling_devices {

			cpucore_cool_cluster0 {
				node_name = "cpucore_cool0";
				device_type = "cpucore";
				dyn_coeff = <0x00>;
				cluster_id = <0x00>;
				min_state = <0x01>;
			};

			gpufreq_cool {
				node_name = "gpufreq_cool0";
				device_type = "gpufreq";
				dyn_coeff = <0x166>;
				cluster_id = <0x00>;
				gpu_pp = <0x02>;
				min_state = <0x190>;
			};

			cpufreq_cool_cluster0 {
				node_name = "cpufreq_cool0";
				device_type = "cpufreq";
				dyn_coeff = <0x73>;
				cluster_id = <0x00>;
				min_state = <0xf4240>;
			};

			gpucore_cool {
				node_name = "gpucore_cool0";
				device_type = "gpucore";
				dyn_coeff = <0x00>;
				cluster_id = <0x00>;
				min_state = <0x01>;
			};
		};

		cpucore_cool0 {
			phandle = <0x31>;
			#cooling-cells = <0x02>;
		};
	};

	ram-dump {
		compatible = "amlogic, ram_dump";
		reg-names = "PREG_STICKY_REG8";
		status = "okay";
		reg = <0x00 0xff6345e0 0x00 0x04>;
		store_device = "data";
	};

	dwc3@ff500000 {
		usb-phy = <0x13 0x14>;
		compatible = "synopsys, dwc3";
		clocks = <0x02 0x41>;
		clock-names = "dwc_general";
		clock-src = "usb3.0";
		status = "okay";
		interrupts = <0x00 0x1e 0x04>;
		phandle = <0xc7>;
		reg = <0x00 0xff500000 0x00 0x100000>;
		cpu-type = "gxl";
	};

	hevc_enc {
		compatible = "cnm, HevcEnc";
		dev_name = "HevcEnc";
		ranges;
		status = "okay";
		#address-cells = <0x02>;
		interrupts = <0x00 0xbb 0x01>;
		#size-cells = <0x02>;
		interrupt-names = "wave420l_irq";

		io_reg_base {
			reg = <0x00 0xff610000 0x00 0x4000>;
		};
	};

	mesonstream {
		compatible = "amlogic, codec, streambuf";
		clocks = <0x02 0x40 0x02 0x39 0x02 0x43 0x02 0x22 0x02 0x0b 0x02 0xa5 0x02 0xae 0x02 0xb7 0x02 0xc0>;
		dev_name = "mesonstream";
		clock-names = "parser_top", "demux", "ahbarb0", "vdec", "clk_81", "clk_vdec_mux", "clk_hcodec_mux", "clk_hevc_mux", "clk_hevcb_mux";
		status = "okay";
	};

	meson-fb {
		mem_alloc = <0x01>;
		compatible = "amlogic, meson-g12a";
		clocks = <0x02 0xc9>;
		dev_name = "meson-fb";
		clock-names = "vpu_clkc";
		status = "disabled";
		interrupts = <0x00 0x03 0x01 0x00 0x38 0x01 0x00 0x59 0x01>;
		display_size_default = <0x1e0 0x320 0x1e0 0x640 0x18>;
		memory-region = <0x2a>;
		mem_size = <0x800000 0x1980000 0x100000 0x100000 0x800000>;
		scale_mode = <0x01>;
		phandle = <0xe8>;
		pxp_mode = <0x00>;
		display_mode_default = "panel";
		interrupt-names = "viu-vsync", "viu2-vsync", "rdma";
		logo_addr = "0x1f800000";
	};

	auge_sound {
		aml-audio-card,effect = <0x6f>;
		aml-audio-card,loopback = <0x6d>;
		compatible = "amlogic, g12a-sound-card";
		aml-audio-card,aux-devs = <0x6e>;
		aml-audio-card,name = "AML-AUGESOUND";
		avout_mute-gpios = <0x4a 0x02 0x00>;

		aml-audio-card,dai-link@3 {
			aml-audio-card,widgets = "Microphone", "Left Microphones", "Microphone", "Right Microphones";
			suffix-name = "alsaPORT-pdm";
			mclk-fs = <0x40>;
			aml-audio-card,routing = "PDM_DIN0", "Left Microphones", "PDM_DIN1", "Right Microphones";

			cpu {
				sound-dai = <0x70>;
			};

			codec {
				sound-dai = <0x71>;
			};
		};
	};

	drm-lcd {
		compatible = "amlogic,drm-lcd";
		dev_name = "meson-lcd";
		status = "okay";
		phandle = <0x10b>;

		ports {

			port {
				#address-cells = <0x01>;
				#size-cells = <0x00>;

				endpoint@0 {
					remote-endpoint = <0x105>;
					phandle = <0x107>;
					reg = <0x00>;
				};
			};
		};
	};

	gpioleds {
		compatible = "gpio-leds";
		status = "okay";

		sys_led {
			gpios = <0x4a 0x05 0x00>;
			label = "sys_led";
			default-state = "on";
		};
	};

	interrupt-controller@2c001000 {
		compatible = "arm,cortex-a15-gic", "arm,cortex-a9-gic";
		#interrupt-cells = <0x03>;
		#address-cells = <0x00>;
		interrupts = <0x01 0x09 0xf04>;
		phandle = <0x01>;
		reg = <0x00 0xffc01000 0x00 0x1000 0x00 0xffc02000 0x00 0x100>;
		interrupt-controller;
	};

	securitykey {
		compatible = "aml, securitykey";
		storage_status = <0x82000065>;
		storage_tell = <0x82000063>;
		storage_remove = <0x82000068>;
		storage_list = <0x82000067>;
		storage_size_func = <0x82000027>;
		storage_set_enctype = <0x8200006a>;
		storage_version = <0x8200006c>;
		storage_block_func = <0x82000025>;
		storage_in_func = <0x82000023>;
		storage_out_func = <0x82000024>;
		storage_read = <0x82000061>;
		storage_write = <0x82000062>;
		storage_query = <0x82000060>;
		storage_verify = <0x82000064>;
		storage_get_enctype = <0x8200006b>;
	};

	vdin1 {
		compatible = "amlogic, vdin";
		dev_name = "vdin1";
		flag_cma = <0x00>;
		status = "disabled";
		interrupts = <0x00 0x55 0x01>;
		phandle = <0xe5>;
		rdma-irq = <0x04>;
		vdin_id = <0x01>;
		reserve-iomap = "true";
	};

	canvas {
		compatible = "amlogic, meson, canvas";
		dev_name = "amlogic-canvas";
		status = "okay";
		phandle = <0xe6>;
		reg = <0x00 0xff638000 0x00 0x2000>;
	};

	locker {
		compatible = "amlogic, audiolocker";
		clocks = <0x23 0x22 0x23 0x23 0x23 0x1a 0x23 0x1b 0x02 0x0d 0x02 0x0e>;
		clock-names = "lock_out", "lock_in", "out_src", "in_src", "out_calc", "in_ref";
		status = "okay";
		interrupts = <0x00 0x01 0x01>;
		phandle = <0x102>;
		dividor = <0x31>;
		interrupt-names = "irq";
		frequency = <0x2ebae40>;
	};

	cpus {
		#address-cells = <0x02>;
		#size-cells = <0x00>;
		phandle = <0x77>;

		cpu@3 {
			compatible = "arm,cortex-a53", "arm,armv8";
			clocks = <0x02 0x17 0x02 0x16 0x02 0x00>;
			cpu-idle-states = <0x0c>;
			device_type = "cpu";
			clock-names = "core_clk", "low_freq_clk_parent", "high_freq_clk_parent";
			hispeed_cpufreq_max = <0x834>;
			voltage-tolerance = <0x00>;
			enable-method = "psci";
			lospeed_cpufreq_max = <0x708>;
			cpu-supply = <0x10>;
			phandle = <0x0b>;
			operating-points-v2 = <0x0d 0x0e 0x0f>;
			medspeed_cpufreq_max = <0x774>;
			reg = <0x00 0x03>;
			diff_tables_supply;
			clock-latency = <0xc350>;
		};

		idle-states {
			entry-method = "arm,psci-0.2";

			cpu-sleep-0 {
				compatible = "arm,idle-state";
				arm,psci-suspend-param = <0x10000>;
				phandle = <0x0c>;
				exit-latency-us = <0x1388>;
				entry-latency-us = <0x1388>;
				local-timer-stop;
				min-residency-us = <0x3a98>;
			};
		};

		cpu@1 {
			compatible = "arm,cortex-a53", "arm,armv8";
			clocks = <0x02 0x17 0x02 0x16 0x02 0x00>;
			cpu-idle-states = <0x0c>;
			device_type = "cpu";
			clock-names = "core_clk", "low_freq_clk_parent", "high_freq_clk_parent";
			hispeed_cpufreq_max = <0x834>;
			voltage-tolerance = <0x00>;
			enable-method = "psci";
			lospeed_cpufreq_max = <0x708>;
			cpu-supply = <0x10>;
			phandle = <0x09>;
			operating-points-v2 = <0x0d 0x0e 0x0f>;
			medspeed_cpufreq_max = <0x774>;
			reg = <0x00 0x01>;
			diff_tables_supply;
			clock-latency = <0xc350>;
		};

		cpu-map {

			cluster0 {
				phandle = <0x78>;

				core0 {
					cpu = <0x08>;
				};

				core3 {
					cpu = <0x0b>;
				};

				core1 {
					cpu = <0x09>;
				};

				core2 {
					cpu = <0x0a>;
				};
			};
		};

		cpu@2 {
			compatible = "arm,cortex-a53", "arm,armv8";
			clocks = <0x02 0x17 0x02 0x16 0x02 0x00>;
			cpu-idle-states = <0x0c>;
			device_type = "cpu";
			clock-names = "core_clk", "low_freq_clk_parent", "high_freq_clk_parent";
			hispeed_cpufreq_max = <0x834>;
			voltage-tolerance = <0x00>;
			enable-method = "psci";
			lospeed_cpufreq_max = <0x708>;
			cpu-supply = <0x10>;
			phandle = <0x0a>;
			operating-points-v2 = <0x0d 0x0e 0x0f>;
			medspeed_cpufreq_max = <0x774>;
			reg = <0x00 0x02>;
			diff_tables_supply;
			clock-latency = <0xc350>;
		};

		cpu@0 {
			compatible = "arm,cortex-a53", "arm,armv8";
			clocks = <0x02 0x17 0x02 0x16 0x02 0x00>;
			cpu-idle-states = <0x0c>;
			device_type = "cpu";
			clock-names = "core_clk", "low_freq_clk_parent", "high_freq_clk_parent";
			hispeed_cpufreq_max = <0x834>;
			voltage-tolerance = <0x00>;
			enable-method = "psci";
			lospeed_cpufreq_max = <0x708>;
			cpu-supply = <0x10>;
			phandle = <0x08>;
			operating-points-v2 = <0x0d 0x0e 0x0f>;
			medspeed_cpufreq_max = <0x774>;
			reg = <0x00 0x00>;
			diff_tables_supply;
			clock-latency = <0xc350>;
		};
	};

	saradc {
		compatible = "amlogic,meson-g12a-saradc";
		clocks = <0x16 0x02 0x103>;
		#io-channel-cells = <0x01>;
		clock-names = "xtal", "saradc_clk";
		status = "okay";
		interrupts = <0x00 0xc8 0x01>;
		phandle = <0x50>;
		reg = <0x00 0xff809000 0x00 0x48>;
	};

	t9015 {
		compatible = "amlogic, aml_codec_T9015";
		#sound-dai-cells = <0x00>;
		status = "okay";
		phandle = <0x6e>;
		reg = <0x00 0xff632000 0x00 0x2000>;
		tdmout_index = <0x01>;
		is_auge_used = <0x01>;
	};

	backlight {
		compatible = "amlogic, backlight-g12a";
		bl_pwm_config = <0x48>;
		pinctrl-1 = <0x10f>;
		bl-gpios = <0x15 0x15 0x00 0x15 0x16 0x00>;
		pinctrl_version = <0x02>;
		key_valid = <0x00>;
		status = "okay";
		pinctrl-0 = <0x46>;
		bl_gpio_names = "GPIOH_4", "GPIOH_5";
		pinctrl-names = "pwm_on", "pwm_off";

		backlight_0 {
			bl_ctrl_method = <0x01>;
			bl_pwm_attr = <0x00 0x7530 0x64 0x00>;
			bl_pwm_en_sequence_reverse = <0x00>;
			bl_pwm_power = <0x01 0x01 0x0a 0x0a>;
			bl_pwm_port = "PWM_F";
			bl_name = "backlight_pwm";
			index = <0x00>;
			bl_level_default_uboot_kernel = <0x64 0x64>;
			bl_level_attr = <0xff 0x01 0x80 0x80>;
			bl_power_attr = <0x00 0x01 0x00 0xc8 0xc8>;
		};

		backlight_1 {
			bl_extern_index = <0x00>;
			bl_ctrl_method = <0x04>;
			bl_name = "bl_extern";
			index = <0x01>;
			bl_level_default_uboot_kernel = <0x64 0x64>;
			bl_level_attr = <0xff 0x0a 0x80 0x80>;
			bl_power_attr = <0x01 0x01 0x00 0xc8 0xc8>;
		};
	};

	drm-amhdmitx {
		compatible = "amlogic,drm-amhdmitx";
		dev_name = "meson-amhdmitx";
		status = "disabled";
		interrupts = <0x00 0x03 0x01>;
		phandle = <0x10a>;
		hdcp = "disabled";

		ports {

			port {
				#address-cells = <0x01>;
				#size-cells = <0x00>;

				endpoint@0 {
					remote-endpoint = <0x104>;
					phandle = <0x106>;
					reg = <0x00>;
				};
			};
		};
	};

	rotary@0 {
		gpios = <0x15 0x09 0x01 0x15 0x0a 0x01>;
		compatible = "rotary-encoder";
		wakeup-source = <0x00>;
		linux,axis = <0x06>;
		rotary-encoder,steps-per-period = <0x02>;
		rotary-encoder,encoding = "gray";
		pinctrl-0 = <0x4c>;
		pinctrl-names = "default";
		rotary-encoder,relative-axis;
	};

	memory@00000000 {
		device_type = "memory";
		linux,usable-memory = <0x00 0x00 0x00 0x20000000>;
		reg = <0x00 0x00 0x00 0x18000000>;
	};

	timer_bc {
		clockevent-rating = <0x12c>;
		compatible = "arm, meson-bc-timer";
		bit_enable = <0x10>;
		timer_name = "Meson TimerF";
		clockevent-features = <0x23>;
		bit_mode = <0x0c>;
		interrupts = <0x00 0x3c 0x01>;
		reg = <0x00 0xffd0f190 0x00 0x04 0x00 0xffd0f194 0x00 0x04>;
		bit_resolution = <0x00>;
		clockevent-shift = <0x14>;
	};

	efuse {
		compatible = "amlogic, efuse";
		clocks = <0x02 0x61>;
		read_cmd = <0x82000030>;
		get_max_cmd = <0x82000033>;
		clock-names = "efuse_clk";
		write_cmd = <0x82000031>;
		status = "okay";
		key = <0x39>;
		phandle = <0xfe>;
	};

	ppmgr {
		compatible = "amlogic, ppmgr";
		dev_name = "ppmgr";
		status = "okay";
		memory-region = <0x53>;
	};

	drm-subsystem {
		compatible = "amlogic,drm-subsystem";
		ports = <0x108>;
		status = "okay";
		phandle = <0x10d>;
	};

	pinctrl@ff634480 {
		compatible = "amlogic,meson-g12a-periphs-pinctrl";
		ranges;
		#address-cells = <0x02>;
		#size-cells = <0x02>;
		phandle = <0x8d>;

		pwm_d_pins2 {
			phandle = <0xac>;

			mux {
				groups = "pwm_d_x6";
				function = "pwm_d";
			};
		};

		spotify_bluetooth_bt_wake_host {
			pins = "GPIOX_6";
			bias-disable;
			phandle = <0xbd>;
			input-enable;
		};

		pdmin {
			phandle = <0x26>;

			mux {
				drive-strength = <0x01>;
				groups = "pdm_din0_a", "pdm_din1_a", "pdm_dclk_a";
				function = "pdm";
			};
		};

		spotify_imu_gpio {
			phandle = <0x1c>;

			mux {
				pins = "GPIOZ_12", "GPIOZ_13";
				bias-pull-down;
			};
		};

		spotify_mfi_i2c_pins {
			phandle = <0x1d>;

			mux {
				bias-disable;
				drive-strength = <0x02>;
				groups = "i2c3_sda_a", "i2c3_sck_a";
				function = "i2c3";
			};
		};

		spicc1_pins {
			phandle = <0xb1>;

			mux {
				drive-strength = <0x01>;
				groups = "spi1_mosi", "spi1_miso", "spi1_clk";
				function = "spi1";
			};
		};

		pwm_e {
			phandle = <0xad>;

			mux {
				groups = "pwm_e";
				function = "pwm_e";
			};
		};

		ee_cecb {
			phandle = <0xb6>;

			mux {
				groups = "cec_ao_b_ee";
				function = "cec_ao_ee";
			};
		};

		rstoutput1 {
			phandle = <0xc1>;

			mux {
				pins = "GPIOZ_3";
				drive-strength = "1";
				bias-pull-up;
				output-high;
			};
		};

		ao_to_sd_uart_pins {
			phandle = <0x93>;

			mux {
				groups = "uart_ao_tx_a_c3", "uart_ao_rx_a_c2";
				function = "uart_ao_a_ee";
				input-enable;
				bias-pull-up;
			};
		};

		sdio_x_clr_pins {
			phandle = <0x99>;

			mux1 {
				output-low;
				groups = "GPIOX_4";
				function = "gpio_periphs";
			};

			mux {
				output-low;
				groups = "GPIOV_0";
				function = "gpio_periphs";
				bias-pull-up;
			};
		};

		emmc_conf_pull_up {
			phandle = <0x2c>;

			mux {
				groups = "emmc_nand_d7", "emmc_nand_d6", "emmc_nand_d5", "emmc_nand_d4", "emmc_nand_d3", "emmc_nand_d2", "emmc_nand_d1", "emmc_nand_d0", "emmc_clk", "emmc_cmd";
				function = "emmc";
				input-enable;
				bias-pull-up;
			};
		};

		i2c0_pins2 {
			phandle = <0x9d>;

			mux {
				drive-strength = <0x02>;
				groups = "i2c0_sda_z0", "i2c0_sck_z1";
				function = "i2c0";
			};
		};

		spotify_disabled_pins_c {
			phandle = <0x4e>;

			mux {
				output-low;
				pins = "GPIOC_0", "GPIOC_1", "GPIOC_2", "GPIOC_3", "GPIOC_5", "GPIOC_6", "GPIOC_7";
				bias-pull-down;
			};
		};

		pwm_c_pins3 {
			phandle = <0xaa>;

			mux {
				groups = "pwm_c_x8";
				function = "pwm_c";
			};
		};

		sdio_x_all_pins {
			phandle = <0x97>;

			mux1 {
				drive-strength = <0x03>;
				groups = "GPIOX_4";
				function = "gpio_periphs";
				bias-pull-up;
				output-high;
			};

			mux {
				drive-strength = <0x03>;
				groups = "GPIOX_0", "GPIOX_1", "GPIOX_2", "GPIOX_3", "GPIOX_5";
				function = "gpio_periphs";
				input-enable;
				bias-pull-up;
			};
		};

		sdio_clk_cmd_pins {
			phandle = <0x94>;

			mux {
				drive-strength = <0x03>;
				groups = "sdio_clk", "sdio_cmd";
				function = "sdio";
				input-enable;
				bias-pull-up;
			};
		};

		i2c3_pins2 {
			phandle = <0xa4>;

			mux {
				drive-strength = <0x02>;
				groups = "i2c3_sda_a", "i2c3_sck_a";
				function = "i2c3";
			};
		};

		spotify_lcd_reset_pin {
			phandle = <0xbc>;

			mux {
				pins = "GPIOZ_5";
				bias-disable;
				drive-strength = "1";
				function = "gpio_periphs";
			};
		};

		cam_dvp_pins {
			phandle = <0xc5>;

			mux {
				groups = "bt656_a_vs", "bt656_a_hs", "bt656_a_clk", "bt656_a_din0", "bt656_a_din1", "bt656_a_din2", "bt656_a_din3", "bt656_a_din4", "bt656_a_din5", "bt656_a_din6", "bt656_a_din7";
				function = "bt656";
			};
		};

		external_eth_pins {
			phandle = <0xb9>;

			mux {
				drive-strength = <0x03>;
				groups = "eth_mdio", "eth_mdc", "eth_rgmii_rx_clk", "eth_rx_dv", "eth_rxd0", "eth_rxd1", "eth_rxd2_rgmii", "eth_rxd3_rgmii", "eth_rgmii_tx_clk", "eth_txen", "eth_txd0", "eth_txd1", "eth_txd2_rgmii", "eth_txd3_rgmii";
				function = "eth";
			};
		};

		spotify_disabled_pins_a {
			phandle = <0x4d>;

			mux {
				output-low;
				pins = "GPIOA_10", "GPIOA_11", "GPIOA_12", "GPIOA_13";
				bias-pull-down;
			};
		};

		internal_gpio_pins {
			phandle = <0xb8>;

			mux {
				bias-disable;
				groups = "GPIOZ_14", "GPIOZ_15";
				function = "gpio_periphs";
				input-enable;
			};
		};

		bl_enable {
			phandle = <0xc2>;

			mux {
				pins = "GPIOH_4";
				function = "gpio_periphs";
				bias-pull-up;
				output-high;
			};
		};

		pwm_c_pins1 {
			phandle = <0xa8>;

			mux {
				groups = "pwm_c_c4";
				function = "pwm_c";
			};
		};

		emmc_conf_pull_done {
			phandle = <0x2d>;

			mux {
				groups = "emmc_nand_ds";
				function = "emmc";
				bias-pull-down;
				input-enable;
			};
		};

		jtag_apee_pin {
			phandle = <0x18>;

			mux {
				groups = "jtag_b_tdi", "jtag_b_tdo", "jtag_b_clk", "jtag_b_tms";
				function = "jtag_b";
			};
		};

		spotify_touch_i2c {
			phandle = <0x19>;

			mux {
				drive-strength = "1";
				groups = "i2c0_sda_z0", "i2c0_sck_z1";
				function = "i2c0";
			};
		};

		pwm_a {
			phandle = <0xa5>;

			mux {
				groups = "pwm_a";
				function = "pwm_a";
			};
		};

		pwm_f_pins1 {
			phandle = <0xae>;

			mux {
				groups = "pwm_f_x";
				function = "pwm_f";
			};
		};

		spotify_bluetooth_host_wake_bt {
			output-enable;
			pins = "GPIOX_7";
			bias-disable;
			drive-strength = "1";
			phandle = <0xbe>;
		};

		pwm_b_pins2 {
			phandle = <0xa7>;

			mux {
				groups = "pwm_b_x19";
				function = "pwm_b";
			};
		};

		i2c2_pins1 {
			phandle = <0xa2>;

			mux {
				drive-strength = <0x02>;
				groups = "i2c2_sda_x", "i2c2_sck_x";
				function = "i2c2";
			};
		};

		spotify_disabled_pins_h {
			phandle = <0x4f>;

			mux {
				output-low;
				pins = "GPIOH_0", "GPIOH_1", "GPIOH_2", "GPIOH_3", "GPIOH_6", "GPIOH_7", "GPIOH_8";
				bias-pull-down;
			};
		};

		bl_pwm_off_pin {
			phandle = <0x47>;

			mux {
				output-low;
				pins = "GPIOH_5";
				drive-strength = "1";
				function = "gpio_periphs";
			};
		};

		eint@0 {
			phandle = <0xbf>;

			mux {
				pins = "GPIOZ_4";
				bias-pull-up;
			};
		};

		gen_clk_ee_z {
			phandle = <0xc4>;

			mux {
				drive-strength = <0x03>;
				groups = "gen_clk_ee_z";
				function = "gen_clk_ee";
			};
		};

		i2c1_pins2 {
			phandle = <0xa0>;

			mux {
				drive-strength = <0x02>;
				groups = "i2c1_sda_h2", "i2c1_sck_h3";
				function = "i2c1";
			};
		};

		sd_clr_all_pins {
			phandle = <0x91>;

			mux1 {
				output-low;
				groups = "GPIOC_4";
				function = "gpio_periphs";
			};

			mux {
				groups = "GPIOC_0", "GPIOC_1", "GPIOC_2", "GPIOC_3", "GPIOC_5";
				function = "gpio_periphs";
				output-high;
			};
		};

		nand_cs {
			phandle = <0x9b>;

			mux {
				groups = "nand_ce0";
				function = "nand";
			};
		};

		all_nand_pins {
			phandle = <0x9a>;

			mux {
				groups = "emmc_nand_d0", "emmc_nand_d1", "emmc_nand_d2", "emmc_nand_d3", "emmc_nand_d4", "emmc_nand_d5", "emmc_nand_d6", "emmc_nand_d7", "nand_ce0", "nand_ale", "nand_cle", "nand_wen_clk", "nand_ren_wr", "nand_rb0";
				function = "nand";
				input-enable;
			};
		};

		tdmin_a {
			phandle = <0x25>;

			mux {
				groups = "tdma_din1";
				function = "tdma_in";
			};
		};

		sd_all_pins {
			phandle = <0x8f>;

			mux1 {
				drive-strength = <0x03>;
				groups = "sdcard_clk_c";
				function = "sdcard";
				bias-pull-up;
				output-high;
			};

			mux {
				drive-strength = <0x03>;
				groups = "sdcard_d0_c", "sdcard_d1_c", "sdcard_d2_c", "sdcard_d3_c", "sdcard_cmd_c";
				function = "sdcard";
				input-enable;
				bias-pull-up;
			};
		};

		i2c0_pins3 {
			phandle = <0x9e>;

			mux {
				drive-strength = <0x02>;
				groups = "i2c0_sda_z7", "i2c0_sck_z8";
				function = "i2c0";
			};
		};

		spotify_rotary {
			phandle = <0x4c>;

			mux {
				pins = "GPIOZ_7", "GPIOZ_8", "GPIOZ_9";
				bias-disable;
				input-enable;
			};
		};

		pwm_d_pins1 {
			phandle = <0xab>;

			mux {
				groups = "pwm_d_x3";
				function = "pwm_d";
			};
		};

		ee_ceca {
			phandle = <0xb5>;

			mux {
				groups = "cec_ao_a_ee";
				function = "cec_ao_ee";
			};
		};

		rstoutput0 {
			phandle = <0xc0>;

			mux {
				output-low;
				pins = "GPIOZ_3";
				drive-strength = "1";
				bias-pull-down;
			};
		};

		spicc0_pins_x {
			phandle = <0xaf>;

			mux {
				drive-strength = <0x01>;
				groups = "spi0_mosi_x", "spi0_miso_x", "spi0_clk_x";
				function = "spi0";
			};
		};

		internal_eth_pins {
			phandle = <0xb7>;

			mux {
				groups = "eth_link_led", "eth_act_led";
				function = "eth";
			};
		};

		spotify_prox_gpio {
			phandle = <0x1b>;

			mux {
				pins = "GPIOZ_10";
				bias-pull-down;
			};
		};

		i2c0_pins1 {
			phandle = <0x9c>;

			mux {
				drive-strength = <0x02>;
				groups = "i2c0_sda_c", "i2c0_sck_c";
				function = "i2c0";
			};
		};

		sdio_x_en_pins {
			phandle = <0x98>;

			mux {
				groups = "sdio_dummy";
				function = "sdio";
				bias-pull-up;
				output-high;
			};
		};

		hdmitx_ddc {
			phandle = <0xb4>;

			mux {
				bias-disable;
				drive-strength = <0x03>;
				groups = "hdmitx_sda", "hdmitx_sck";
				function = "hdmitx";
			};
		};

		pwm_c_pins2 {
			phandle = <0xa9>;

			mux {
				groups = "pwm_c_x5";
				function = "pwm_c";
			};
		};

		sd_clk_cmd_pins {
			phandle = <0x8e>;

			mux1 {
				drive-strength = <0x03>;
				groups = "sdcard_clk_c";
				function = "sdcard";
				bias-pull-up;
				output-high;
			};

			mux {
				drive-strength = <0x03>;
				groups = "sdcard_cmd_c";
				function = "sdcard";
				input-enable;
				bias-pull-up;
			};
		};

		spdifin {
			status = "disabled";
			phandle = <0xba>;
		};

		i2c3_pins1 {
			phandle = <0xa3>;

			mux {
				drive-strength = <0x02>;
				groups = "i2c3_sda_h", "i2c3_sck_h";
				function = "i2c3";
			};
		};

		c_uart {
			phandle = <0x29>;

			mux {
				groups = "uart_tx_c", "uart_rx_c";
				function = "uart_c";
			};
		};

		tdmout_a {
			phandle = <0x24>;

			mux {
				groups = "tdma_sclk", "tdma_fs", "tdma_dout0";
				function = "tdma_out";
			};
		};

		pwm_f_pins2 {
			phandle = <0x46>;

			mux {
				groups = "pwm_f_h";
				function = "pwm_f";
			};
		};

		sd_1bit_pins {
			phandle = <0x90>;

			mux1 {
				drive-strength = <0x03>;
				groups = "sdcard_clk_c";
				function = "sdcard";
				bias-pull-up;
				output-high;
			};

			mux {
				drive-strength = <0x03>;
				groups = "sdcard_d0_c", "sdcard_cmd_c";
				function = "sdcard";
				input-enable;
				bias-pull-up;
			};
		};

		new_bl_pin {
			phandle = <0x10f>;

			mux {
				output-low;
				pins = "GPIOH_5";
				drive-strength = "1";
				function = "gpio_periphs";
			};
		};

		spicc0_pins_c {
			phandle = <0xb0>;

			mux {
				drive-strength = <0x01>;
				groups = "spi0_mosi_c", "spi0_miso_c", "spi0_ss0_c", "spi0_clk_c";
				function = "spi0";
			};
		};

		spotify_buttons {
			phandle = <0x4b>;

			mux {
				pins = "GPIOA_0", "GPIOA_1", "GPIOA_2", "GPIOA_3", "GPIOAO_3", "GPIOA_5";
				bias-disable;
				input-enable;
			};
		};

		i2c2_pins2 {
			phandle = <0x1a>;

			mux {
				drive-strength = <0x02>;
				groups = "i2c2_sda_z", "i2c2_sck_z";
				function = "i2c2";
			};
		};

		b_uart {
			phandle = <0x28>;

			mux {
				groups = "uart_tx_b", "uart_rx_b";
				function = "uart_b";
			};
		};

		pwm_b_pins1 {
			phandle = <0xa6>;

			mux {
				groups = "pwm_b_x7";
				function = "pwm_b";
			};
		};

		i2c1_pins3 {
			phandle = <0xa1>;

			mux {
				drive-strength = <0x02>;
				groups = "i2c1_sda_h6", "i2c1_sck_h7";
				function = "i2c1";
			};
		};

		sdio_all_pins {
			phandle = <0x95>;

			mux {
				drive-strength = <0x03>;
				groups = "sdio_d0", "sdio_d1", "sdio_d2", "sdio_d3", "sdio_clk", "sdio_cmd";
				function = "sdio";
				input-enable;
				bias-pull-up;
			};
		};

		sd_clr_noall_pins {
			phandle = <0x92>;

			mux {
				groups = "GPIOC_0", "GPIOC_1", "GPIOC_4", "GPIOC_5";
				function = "gpio_periphs";
				output-high;
			};
		};

		sdio_x_clk_cmd_pins {
			phandle = <0x96>;

			mux1 {
				drive-strength = <0x03>;
				groups = "GPIOX_4";
				function = "gpio_periphs";
				bias-pull-up;
				output-high;
			};

			mux {
				drive-strength = <0x03>;
				groups = "GPIOX_5";
				function = "gpio_periphs";
				input-enable;
				bias-pull-up;
			};
		};

		banks@ff6346c0 {
			reg-names = "mux", "pull", "pull-enable", "gpio", "drive-strength";
			gpio-controller;
			phandle = <0x15>;
			reg = <0x00 0xff6346c0 0x00 0x40 0x00 0xff6344e8 0x00 0x18 0x00 0xff634520 0x00 0x18 0x00 0xff634440 0x00 0x4c 0x00 0xff634740 0x00 0x1c>;
			#gpio-cells = <0x02>;
		};

		hdmitx_hpd {
			phandle = <0xb2>;

			mux {
				bias-disable;
				groups = "hdmitx_hpd_in";
				function = "hdmitx";
			};
		};

		emmc_clk_cmd_pins {
			phandle = <0x2b>;

			mux {
				groups = "emmc_clk", "emmc_cmd";
				function = "emmc";
				input-enable;
				bias-pull-up;
			};
		};

		i2c1_pins1 {
			phandle = <0x9f>;

			mux {
				drive-strength = <0x02>;
				groups = "i2c1_sda_x", "i2c1_sck_x";
				function = "i2c1";
			};
		};

		clk12_24_z_pins {
			phandle = <0xc3>;

			mux {
				drive-strength = <0x03>;
				groups = "clk12_24_z";
				function = "clk12_24_ee";
			};
		};

		a_uart {
			phandle = <0x27>;

			mux {
				groups = "uart_tx_a", "uart_rx_a", "uart_cts_a", "uart_rts_a";
				function = "uart_a";
			};
		};

		spotify_touch_gpio {
			phandle = <0xbb>;

			mux {
				drive-strength = "1";
				groups = "GPIOZ_3", "GPIOZ_4";
				function = "gpio_periphs";
			};
		};

		hdmitx_hpd_gpio {
			phandle = <0xb3>;

			mux {
				bias-disable;
				groups = "GPIOH_1";
				function = "gpio_periphs";
			};
		};
	};

	rtc {
		compatible = "amlogic, aml_vrtc";
		alarm_reg_addr = <0xff8000a8>;
		timer_e_addr = <0xffd0f188>;
		status = "okay";
		init_date = "2015/01/01";
	};

	serial@ffd22000 {
		compatible = "amlogic, meson-uart";
		clocks = <0x16 0x02 0x3c>;
		fifosize = <0x40>;
		clock-names = "clk_uart", "clk_gate";
		status = "disabled";
		interrupts = <0x00 0x5d 0x01>;
		phandle = <0xe3>;
		reg = <0x00 0xffd22000 0x00 0x18>;
		pinctrl-0 = <0x29>;
		pinctrl-names = "default";
	};

	ge2d {
		compatible = "amlogic, ge2d-g12a";
		clocks = <0x02 0x95 0x02 0x3d 0x02 0x96>;
		dev_name = "ge2d";
		clock-names = "clk_vapb_0", "clk_ge2d", "clk_ge2d_gate";
		status = "okay";
		interrupts = <0x00 0x92 0x01>;
		reg = <0x00 0xff940000 0x00 0x10000>;
		interrupt-names = "ge2d";
	};

	emmc@ffe07000 {
		cap-mmc-highspeed;
		compatible = "amlogic, meson-mmc-g12a";
		clocks = <0x02 0x35 0x02 0x72 0x02 0x02 0x02 0x05 0x16>;
		cap-sd-highspeed;
		pinctrl-1 = <0x2c 0x2d>;
		clock-names = "core", "clkin0", "clkin1", "clkin2", "xtal";
		status = "okay";
		interrupts = <0x00 0xbf 0x01>;
		disable-wp;
		bus-width = <0x08>;
		phandle = <0xe9>;
		reg = <0x00 0xffe07000 0x00 0x800>;
		pinctrl-0 = <0x2b>;
		non-removable;
		max-frequency = <0xbebc200>;
		pinctrl-names = "emmc_clk_cmd_pins", "emmc_all_pins";

		emmc {
			max_req_size = <0x20000>;
			caps2 = "MMC_CAP2_HS200";
			gpio_dat3 = <0x15 0x1d 0x00>;
			f_min = <0x61a80>;
			card_type = <0x01>;
			f_max = <0xbebc200>;
			ocr_avail = <0x200080>;
			hw_reset = <0x15 0x26 0x00>;
			co_phase = <0x03>;
			tx_delay = <0x00>;
			pinname = "emmc";
			caps = "MMC_CAP_8_BIT_DATA", "MMC_CAP_MMC_HIGHSPEED", "MMC_CAP_SD_HIGHSPEED", "MMC_CAP_NONREMOVABLE", "MMC_CAP_HW_RESET", "MMC_CAP_ERASE", "MMC_CAP_CMD23";
			calc_f = <0x01>;
		};
	};

	vout2 {
		compatible = "amlogic, vout2";
		clocks = <0x02 0xc4 0x02 0xc9>;
		dev_name = "vout";
		clock-names = "vpu_clkc0", "vpu_clkc";
		status = "okay";
	};
};
